[part 1 of 2: packages /DataType to /ComponentType/IvtrUSetCtrl/IvtrUSetCtrlMAIN]
AUTOSAR XML (schema 4.0)
package /DataType
  5 x app type, all with category=VALUE:
    Perc7: compu {phys=raw*0.05 for raw 0..2000; unit %}, range phys 0..100 %
    PrpsnPwrLimMin: compu {phys=raw*0.5-511 for raw 0..1022; unit kW}, range phys -511..0 kW
    Undefined: compu {identical; unit Unitless}
    T3: compu {phys=raw-50 for raw 0..250; unit degC}, range phys -50..200 degC  # Intake Air Temperature DegC
    HvCoolg1: compu {0=HvCoolg1_NoRequestForMoreCoolantPower, 1=HvCoolg1_IncreaseLevel1ForMoreCoolantPower, 2=HvCoolg1_IncreaseLevel2ForMoreCoolantPower, 3=HvCoolg1_MaxCoolingPower, 4=HvCoolg1_NotDefined; unit Unitless}, range raw 0..4
  application record data type VehModMngtGlbSafe1: category=STRUCTURE
    10 x application record element, all with category=VALUE:
      UsgModSts: compu-method=UsgModSts1, range raw 0..13, type=UsgModSts1
      CarModSts1: compu-method=CarModSts1, range raw 0..5, type=CarModSts1  # Main CarMode Data
      CarModSubtypWdCarModSubtyp: compu {identical; unit Unitless}, range phys 0..7 Unitless, type=Nr5  # CarMode Sub Data
      EgyLvlElecMai: compu {identical; unit Unitless}, range phys 0..15 Unitless, type=UInt4  # Main Data for ElEnergyLevel
      EgyLvlElecSubtyp: compu {identical; unit Unitless}, range phys 0..15 Unitless, type=UInt4  # Sub Data ElEnergyLevel
      PwrLvlElecMai: compu {identical; unit Unitless}, range phys 0..15 Unitless, type=UInt4  # Main Data for ElPowerLevel
      PwrLvlElecSubtyp: compu {identical; unit Unitless}, range phys 0..15 Unitless, type=UInt4  # Sub Data for ElPowerLevel
      FltEgyCnsWdSts: compu {0=FltEgyCns1_NoFlt, 1=FltEgyCns1_Flt; unit Unitless}, range raw 0..1, type=FltEgyCns1  # Energy Consumption Fault
      Chks: compu {identical; unit Unitless}, range phys 0..255 Unitless, type=UInt8  # End to End Checksum
      Cntr: compu {identical; unit Unitless}, range phys 0..15 Unitless, type=UInt4  # End to End Counter
  16 x app type, all with category=VALUE:
    UsgModSts1: compu-method=UsgModSts1, range raw 0..13  # UsageMode Data
    CarModSts1: compu-method=CarModSts1, range raw 0..5
    Nr5: compu {identical; unit Unitless}, range phys 0..7 Unitless  # 0= Normal 1= 2= 3= 4= 5= 6= 7=
    UInt8: compu {identical; unit Unitless}, range phys 0..255 Unitless
    UInt4: compu {identical; unit Unitless}, range phys 0..15 Unitless
    FltEgyCns1: compu {0=FltEgyCns1_NoFlt, 1=FltEgyCns1_Flt; unit Unitless}, range raw 0..1
    U2: compu {phys=raw*0.025+10.6 for raw 0..216; unit Volt}, range phys 10.6..16 Volt  # Voltage in Volt Resolution: 0.1 Range: 10.6 - 16.0 V
    I5: compu {identical; unit A}, range phys 0..254 A, invalid-value=255
    HvActvnSts: compu {0=HvActvnSts_Open, 1=HvActvnSts_Clsd, 2=HvActvnSts_KeepSt, 3=HvActvnSts_OpenAndReqActvDcha; unit Unitless}, range raw 0..3
    Perc2: compu {phys=raw*0.5 for raw 0..200; unit %}, range phys 0..100 %  # Throttle postition 0-100%
    EngSt1: compu {0=EngSt1_Ini, 1=EngSt1_Awake, 2=EngSt1_Rdy, 3=EngSt1_PreStrtg, 4=EngSt1_StrtgInProgs, 5=EngSt1_RunngRunng, 6=EngSt1_RunngStb, 7=EngSt1_RunngStrtgInProgs, 8=EngSt1_RunngRemStrtd, 9=EngSt1_AftRun; unit Unitless}, range raw 0..9
    OkNotOk1: compu {0=OkNotOk1_Ok, 1=OkNotOk1_NotOk; unit Unitless}, range raw 0..1
    UInt16: compu {identical; unit Unitless}, range phys 0..65535 Unitless
    CarTiGlb: compu {phys=raw*0.1 for raw 0..4294967295; unit s}, range phys 0..429496729.4 s, invalid-value=4.294967295E8
    DcDcActvd: compu {0=DcDcActvd_NoConversionToLVSide, 1=DcDcActvd_ConversionToLVSide; unit Unitless}, range raw 0..1
    CooltFlowForDtElec1: compu {phys=raw*0.01 for raw 0..1023; unit L / min}, range phys 0..10.23 L / min  # Flow rate in litres per minute.
  application record data type IsgTqAllwd1: category=STRUCTURE
    application record element IsgTqAllwdChks: category=VALUE, compu {phys=raw for raw 0..255; unit Unitless}, range phys 0..255 Unitless, type=Chks8  # Checksum
    application record element IsgTqAllwdCntr: category=VALUE, compu {phys=raw for raw 0..15; unit Unitless}, range phys 0..15 Unitless, type=Cntr4  # Counter
    application record element IsgTqAllwd: category=VALUE, compu {identical; unit Unitless}, range phys 0..15 Unitless, type=Nr37
  26 x app type, all with category=VALUE:
    Chks8: compu {phys=raw for raw 0..255; unit Unitless}, range phys 0..255 Unitless  # 8 bit checksum
    Nr37: compu {identical; unit Unitless}, range phys 0..15 Unitless
    Cntr4: compu {phys=raw for raw 0..15; unit Unitless}, range phys 0..15 Unitless  # 4 bit counter used in checksum calculation. N=E (modulo 16)
    SpdActInt: compu {identical; unit rpm}, range phys -INF..INF rpm
    DIOPinSts: compu {0=DIOPinSts_Low, 1=DIOPinSts_High; unit Unitless}, range raw 0..1
    NotCmpl1: compu {0=NotCmpl1_NotCmpl, 1=NotCmpl1_Cmpl; unit Unitless}, range raw 0..1  # Describe a general status as 'complete' or 'not complte'.
    N1: compu {phys=raw*0.5 for raw 0..32767; unit rpm}, range phys 0..16383.5 rpm
    ComTiOut: compu {0=ComTiOut_NoTimeout, 1=ComTiOut_Timeout; unit Unitless}, range raw 0..1
    OnOff1: compu {0=OnOff1_Off, 1=OnOff1_On; unit Unitless}, range raw 0..1
    TqInt: compu {identical; unit NewtonMeter}, range phys -50000..50000 NewtonMeter
    IsgModTyp1: compu {0=IsgModTyp1_Inin, 1=IsgModTyp1_Stb, 2=IsgModTyp1_TqCtrl, 3=IsgModTyp1_SpdCtrl, 4=IsgModTyp1_UDcCtrl, 5=IsgModTyp1_PreChrg, 6=IsgModTyp1_PwrDwn, 7=IsgModTyp1_Flt; unit Unitless}, range raw 0..7  # Coding # Meaning 0 Initialization 1 Standby 2 Torque Control 3 Speed Control 4 DC Voltage control 5 Pre-charge 6 Power-down 7 Fault
    IntFlw: compu {identical; unit L / min}, range phys -INF..INF L / min
    CooltInhb: compu {0=CooltInhb_CoolntFlowReqToEngAllwd, 1=CooltInhb_CoolntFlowReqToEngNotAllwd; unit Unitless}, range raw 0..1
    IntT: compu {identical; unit degC}, range phys -INF..INF degC
    EngTLoFlg: compu {0=EngTLoFlg_ActvLoTForEng, 1=EngTLoFlg_DeactvLoTForEng; unit Unitless}, range raw 0..1
    TInt: compu {identical; unit degC}, range phys -300..1000 degC
    ImobSnsr: compu {identical; unit Unitless}, range phys -INF..INF Unitless
    TestResult: compu {0=TestResult_NotCompleted, 1=TestResult_Failed, 2=TestResult_Passed; unit Unitless}, range raw 0..2
    EradSpdIntFloat1: compu {identical; unit rpm}, range phys -20000..20000 rpm
    TqAllwdPosAndNeg2: compu {0=TqAllwdPosAndNeg2_NoTq, 1=TqAllwdPosAndNeg2_Pos, 2=TqAllwdPosAndNeg2_Neg, 3=TqAllwdPosAndNeg2_PosAndNeg; unit Unitless}, range raw 0..3
    TqArbMgrCtrl: compu {0=TqArbMgrCtrl_TqOff, 1=TqArbMgrCtrl_TqCtrl, 2=TqArbMgrCtrl_SpdCtrl, 3=TqArbMgrCtrl_UdcCtrl; unit Unitless}, range raw 0..3
    MotCtrlMod: compu {0=MotCtrlMod_TqOff, 1=MotCtrlMod_TqOn, 2=MotCtrlMod_OffsetAngleCalibration, 3=MotCtrlMod_ActDcha, 4=MotCtrlMod_ThreePhaShoCirc; unit Unitless}, range raw 0..4
    IDcInt: compu {identical; unit A}, range phys -1000..1000 A
    HvT1: compu {phys=raw-40 for raw 0..255; unit degC}, range phys -40..215 degC
    HvU1: compu {phys=raw*0.25 for raw 0..2044; unit Volt}, range phys 0..511 Volt  # Defining the voltage data type used for HV components.
    PrpsnPwrLimMax: compu {phys=raw*0.5 for raw 0..1022; unit kW}, range phys 0..511 kW
  application record data type TqRngInt: category=STRUCTURE
    application record element Min: category=VALUE, compu {identical; unit NewtonMeter}, range phys -50000..50000 NewtonMeter, type=TqInt  # Minimum value
    application record element Max: category=VALUE, compu {identical; unit NewtonMeter}, range phys -50000..50000 NewtonMeter, type=TqInt  # Maximum value
  15 x app type:
    Boolean: category=BOOLEAN, compu {0=Boolean_FALSE, 1=Boolean_TRUE; unit Unitless}, range raw 0..1
    ActvDcha: category=VALUE, compu {0=ActvDcha_NoDischarge, 1=ActvDcha_Discharge; unit Unitless}, range raw 0..1
    HvIlckSts: category=VALUE, compu {0=HvIlckSts_HvilOpen, 1=HvIlckSts_HvilClosed; unit Unitless}, range raw 0..1
    SleepReq: category=VALUE, compu {0=SleepReq_NoRequest, 1=SleepReq_SleepRequested; unit Unitless}, range raw 0..1
    TestRequest: category=VALUE, compu {0=TestRequest_NoRequest, 1=TestRequest_TestRequested; unit Unitless}, range raw 0..1
    USetCtrlModType: category=VALUE, compu {0=USetCtrlModType_USetCtrlOff, 1=USetCtrlModType_USetCtrlOn; unit Unitless}, range raw 0..1
    SpdSetCtrlMod: category=VALUE, compu {0=SpdSetCtrlMod_SpdCtrlOff, 1=SpdSetCtrlMod_SpdCtrlExt, 2=SpdSetCtrlMod_SpdCtrlCltch, 3=SpdSetCtrlMod_SpdCtrlTrsm, 4=SpdSetCtrlMod_SpdCtrlZero; unit Unitless}, range raw 0..4
    CalJobReq: category=VALUE, compu {0=CalJobReq_NoCalReq, 1=CalJobReq_OffsetAngleCalReq; unit Unitless}, range raw 0..1
    UInt32: category=VALUE, compu {identical; unit Unitless}, range phys 0..4294967295 Unitless
    ModSts: category=VALUE, compu {0=ModSts_PreInit, 1=ModSts_LvInit, 2=ModSts_HvInit, 3=ModSts_Stb, 4=ModSts_TqCtrl, 5=ModSts_SpdCtrl, 6=ModSts_SyncnCtrl, 7=ModSts_UDcCtrl, 8=ModSts_Flt, 9=ModSts_PreSleep, 10=ModSts_ActvDcha, 11=ModSts_PreStb, 12=ModSts_GearSyncn; unit Unitless}, range raw 0..12
    ImobSts: category=VALUE, compu {0=ImobSts_ImobUndefd, 1=ImobSts_ImobImobn, 2=ImobSts_ImobMtn, 3=ImobSts_ImobNoMtn; unit Unitless}, range raw 0..3
    DiDiag: category=VALUE, compu {0=DiDiag_Disable, 1=DiDiag_Enable; unit Unitless}, range raw 0..1
    OnOff2: category=VALUE, compu {0=OnOff2_On, 1=OnOff2_Off; unit Unitless}, range raw 0..1  # PLILJESS: Autosar AI Tables Standard DATA-TYPE. Please consider using OnOff1 first hand to avoid confusion.
    TrsmVehSpd: category=VALUE, compu {phys=raw*0.01 for raw 0..65535; unit Km/h}, range phys 0..320 Km/h, invalid-value=655.35
    Perc5: category=VALUE, compu {phys=raw*0.3921568627 for raw 0..255; unit %}, range phys 0..100 %
  application record data type EngNSafe: category=STRUCTURE
    4 x application record element, all with category=VALUE:
      EngN: compu {phys=raw*0.5 for raw 0..32767; unit rpm}, range phys 0..16383 rpm, invalid-value=16383.5, type=N30
      EngNGrdt: compu {phys=raw for raw -30000..32767; unit RpmPerSec}, range phys -30000..30000 RpmPerSec, invalid-value=32767, type=NGrdt1
      EngNChks: compu {identical; unit Unitless}, range phys 0..255 Unitless, type=UInt8
      EngNCntr: compu {identical; unit Unitless}, range phys 0..15 Unitless, type=UInt4
  4 x app type, all with category=VALUE:
    N30: compu {phys=raw*0.5 for raw 0..32767; unit rpm}, range phys 0..16383 rpm, invalid-value=16383.5  # Engine speed RPM. Invalid valie 16383.5.
    NGrdt1: compu {phys=raw for raw -30000..32767; unit RpmPerSec}, range phys -30000..30000 RpmPerSec, invalid-value=32767  # Unit rpm/s
    CrashSts3: compu {0=CrashSts3_Resd1, 1=CrashSts3_NoCrash, 2=CrashSts3_Crash, 3=CrashSts3_Resd2; unit Unitless}, range raw 0..3  # Information regarding if the vehicle just has been involved in a crash, which has been detected by the SRS ECU.
    Spd6: compu {phys=raw*0.003906369 for raw -7679..7680; unit m/s}, range phys -30..30 m/s  # Generic speed data type 6
  application record data type EngT: category=STRUCTURE
    application record element EngT: category=VALUE, compu {phys=raw-50 for raw 0..250; unit degC}, range phys -50..200 degC, type=T3  # Engine coolant temperature
    application record element EngTQf: category=VALUE, compu-method=Qf1, range raw 0..3, type=Qf1  # Engine coolant temperature Qf flag
  app type Qf1: category=VALUE, compu-method=Qf1, range raw 0..3
  app type TrsmMotShiftSpdSyncnReq: category=VALUE, compu {phys=raw-16384 for raw 0..32767; unit Unitless}, range phys -16384..16383 Unitless
  app type CooltTHiResl: category=VALUE, compu {phys=raw*0.1-40 for raw 0..1800; unit degC}, range phys -40..140 degC
  application record data type UDcRngInt: category=STRUCTURE
    application record element Min: category=VALUE, compu {identical; unit Volt}, range phys -100000..100000 Volt, type=UDcInt  # Minimum value
    application record element Max: category=VALUE, compu {identical; unit Volt}, range phys -100000..100000 Volt, type=UDcInt  # Maximum value
  app type UDcInt: category=VALUE, compu {identical; unit Volt}, range phys -100000..100000 Volt
  application record data type PtTqAtAxleReMinReqRec1: category=STRUCTURE
    application record element PtTqAtAxleReMinReq: category=VALUE, compu {phys=raw for raw -20000..20000; unit NewtonMeter}, range phys -20000..20000 NewtonMeter, type=Tq2  # Minimum allowed powertrain applied torque on the rear axle
    application record element PtTqAtAxleReMinReqChks: category=VALUE, compu {identical; unit Unitless}, range phys 0..255 Unitless, type=UInt8  # Checksum
    application record element PtTqAtAxleReMinReqCntr: category=VALUE, compu {identical; unit Unitless}, range phys 0..15 Unitless, type=UInt4  # Counter
  app type Tq2: category=VALUE, compu {phys=raw for raw -20000..20000; unit NewtonMeter}, range phys -20000..20000 NewtonMeter
  app type WhlMotSysActvDampgModCodSts: category=VALUE, compu {0=WhlMotSysActvDampgModCodSts_NoDampg, 1=WhlMotSysActvDampgModCodSts_LoDampg, 2=WhlMotSysActvDampgModCodSts_MedDampg, 3=WhlMotSysActvDampgModCodSts_HiDampg; unit Unitless}, range raw 0..3  # Request of torsional active damping mode for shuffle mitigation (anti-shuffle). The signal is used to turn off anti-shuffle damping or to request extra anti-shuffle damping
  application record data type VehSpdLgtSafe1: category=STRUCTURE
    4 x application record element, all with category=VALUE:
      VehSpdLgt: compu {phys=raw*0.00391 for raw 0..31970; unit m/s}, range phys 0..125 m/s, type=Spd1  # Vehicle speed longitudinal
      VehSpdLgtQf: compu-method=GenQf1, range raw 0..3, type=GenQf1  # Qf for vehicle speed longitudinal
      VehSpdLgtCntr: compu {identical; unit Unitless}, range phys 0..15 Unitless, type=UInt4  # Counter for vehicle speed longitudinal checksum calculation
      VehSpdLgtChks: compu {identical; unit Unitless}, range phys 0..255 Unitless, type=UInt8  # Checksum for vehicle speed longitudinal
  app type Spd1: category=VALUE, compu {phys=raw*0.00391 for raw 0..31970; unit m/s}, range phys 0..125 m/s
  app type GenQf1: category=VALUE, compu-method=GenQf1, range raw 0..3
  app type PtActrMod1: category=VALUE, compu {0=PtActrMod1_NoReq, 1=PtActrMod1_ActrMod1, 2=PtActrMod1_ActrMod2, 3=PtActrMod1_ActrMod3; unit Unitless}, range raw 0..3
  application record data type PwrRngInt: category=STRUCTURE
    application record element Min: category=VALUE, compu {identical; unit kW}, range phys -20000..20000 kW, type=PwrInt  # Minimum Value
    application record element Max: category=VALUE, compu {identical; unit kW}, range phys -20000..20000 kW, type=PwrInt  # Maximum Value
  app type PwrInt: category=VALUE, compu {identical; unit kW}, range phys -20000..20000 kW
  app type PtTqType: category=VALUE, compu {phys=raw-1024 for raw 0..2047; unit NewtonMeter}, range phys -1024..1023 NewtonMeter
  application record data type VehMtnStSafe1: category=STRUCTURE
    application record element VehMtnSt: category=VALUE, compu-method=VehMtnSt2, range raw 0..7, type=VehMtnSt2  # Vehicle motion state
    application record element VehMtnStChks: category=VALUE, compu {identical; unit Unitless}, range phys 0..255 Unitless, type=UInt8  # Checksum for vehicle motion state
    application record element VehMtnStCntr: category=VALUE, compu {identical; unit Unitless}, range phys 0..15 Unitless, type=UInt4  # Counter for vehicle motion state
  app type VehMtnSt2: category=VALUE, compu-method=VehMtnSt2, range raw 0..7
  app type CooltLoFlow: category=VALUE, compu {phys=raw*0.5 for raw 0..40; unit L / min}, range phys 0..20 L / min
  application record data type Rec32ByteU32ReadFlg: category=STRUCTURE
    9 x application record element, all with category=VALUE:
      MemReadFlg: compu {0=OkNotOk_NotOk, 1=OkNotOk_Ok; unit Unitless}, range raw 0..1, type=OkNotOk  # Memory has been read from memory and has been checked for corruption.
      Byte00To03: compu {identical; unit Unitless}, range phys 0..4294967295 Unitless, type=UInt32  # Byte 00 to 03 in big endian byte order.
      Byte04To07: compu {identical; unit Unitless}, range phys 0..4294967295 Unitless, type=UInt32  # Byte 04 to 07 in big endian byte order.
      Byte08To11: compu {identical; unit Unitless}, range phys 0..4294967295 Unitless, type=UInt32  # Byte 08 to 11 in big endian byte order.
      Byte12To15: compu {identical; unit Unitless}, range phys 0..4294967295 Unitless, type=UInt32  # Byte 12 to 15 in big endian byte order.
      Byte16To19: compu {identical; unit Unitless}, range phys 0..4294967295 Unitless, type=UInt32  # Byte 16 to 19 in big endian byte order.
      Byte20To23: compu {identical; unit Unitless}, range phys 0..4294967295 Unitless, type=UInt32  # Byte 20 to 23 in big endian byte order.
      Byte24To27: compu {identical; unit Unitless}, range phys 0..4294967295 Unitless, type=UInt32  # Byte 24 to 27 in big endian byte order.
      Byte28To31: compu {identical; unit Unitless}, range phys 0..4294967295 Unitless, type=UInt32  # Byte 28 to 31 in big endian byte order.
  4 x app type, all with category=VALUE:
    OkNotOk: compu {0=OkNotOk_NotOk, 1=OkNotOk_Ok; unit Unitless}, range raw 0..1
    IsgMotCooltFlow: compu {phys=raw*0.05 for raw 0..1023; unit L / min}, range phys 0..51.15 L / min
    HvI1: compu {phys=raw*0.1-410 for raw 0..8191; unit A}, range phys -410..409.1 A
    DchaAvl: compu {0=DchaAvl_NotAvailable, 1=DchaAvl_Available, 2=DchaAvl_BackupOnly, 3=DchaAvl_Reserved; unit Unitless}, range raw 0..3
  application record data type ImobEngChk: category=STRUCTURE
    8 x application record element, all with category=VALUE:
      ImobEngChkSts: compu {0=AvlSts2_NotAvl, 1=AvlSts2_Avl; unit Unitless}, range raw 0..1, type=AvlSts2  # Message to CEM Challenge available
      ImobEngDataChk{0..6}: compu {identical; unit Unitless}, range phys 0..255 Unitless, type=UInt8  # Byte {0..6}
  app type AvlSts2: category=VALUE, compu {0=AvlSts2_NotAvl, 1=AvlSts2_Avl; unit Unitless}, range raw 0..1  # Availability status 0= not available 1= available
  app type ImobMemSts: category=VALUE, compu {identical; unit Unitless}, range phys 0..255 Unitless
  application record data type ImobEngMgrReq: category=STRUCTURE
    8 x application record element, all with category=VALUE:
      ImobEngMgrCmdTar1: compu-method=ImobEngMgrReqCmd, range raw 0..3, type=ImobEngMgrReqCmd  # Command from CEM
      ImobEngDataMgrReq{0..6}: compu {identical; unit Unitless}, range phys 0..255 Unitless, type=UInt8  # Byte {0..6}
  app type ImobEngMgrReqCmd: category=VALUE, compu-method=ImobEngMgrReqCmd, range raw 0..3
  app type IsgSpd1: category=VALUE, compu {identical; unit rpm}, range phys 0..8191 rpm  # ISG speed referred to crankshaft.
  application record data type VehCfgPrm: category=STRUCTURE
    8 x application record element, all with category=VALUE, compu {phys=raw for raw 0..255; unit Unitless}, range phys 0..255 Unitless, type=Nr2:
      BlkIDBytePosn1  # Block ID for specific Car Configuration parameter sequence
      CCPBytePosn2  # 1st position in specific CCP number sequence - Block ID dependant
      CCPBytePosn3  # 2nd position in specific CCP number sequence - Block ID dependant
      CCPBytePosn4  # 3rd position in specific CCP number sequence - Block ID dependant
      CCPBytePosn5  # 4th position in specific CCP number sequence - Block ID dependant
      CCPBytePosn6  # 5th position in specific CCP number sequence - Block ID dependant
      CCPBytePosn7  # 6th position in specific CCP number sequence - Block ID dependant
      CCPBytePosn8  # 7th position in specific CCP number sequence - Block ID dependant
  app type Nr2: category=VALUE, compu {phys=raw for raw 0..255; unit Unitless}, range phys 0..255 Unitless
  app type HvFltInfo1: category=VALUE, compu {0=HvFltInfo1_NoFlt1, 1=HvFltInfo1_ElecMotFlt, 2=HvFltInfo1_ShoCircMotAcPha, 3=HvFltInfo1_InvrNoHvDc, 4=HvFltInfo1_InvrFlt1, 5=HvFltInfo1_ShoCircDcPha, 6=HvFltInfo1_Undefined1; unit Unitless}, range raw 0..6  # Datat type defining the different fault states which are applicable for the inverter fault signal.
  app type Len31: category=VALUE, compu {phys=raw for raw 0..2000000; unit km}, range phys 0..2000000 km
  application record data type LvlElecSts1: category=STRUCTURE
    application record element LvlElecMai: category=VALUE, compu {identical; unit Unitless}, range phys 0..15 Unitless, type=UInt4
    application record element LvlElecSubtyp: category=VALUE, compu {identical; unit Unitless}, range phys 0..15 Unitless, type=UInt4
  application record data type SysU: category=STRUCTURE  # System voltage represented by the CEM node Voltage
    application record element SysU: category=VALUE, compu {phys=raw*0.1 for raw 0..250; unit Volt}, range phys 0..25 Volt, type=U1  # System Voltage
    application record element SysUQf: category=VALUE, compu-method=GenQf1, range raw 0..3, type=GenQf1  # System voltaeg quality factor
  app type U1: category=VALUE, compu {phys=raw*0.1 for raw 0..250; unit Volt}, range phys 0..25 Volt
  application record data type IsgTqActSafe1: category=STRUCTURE  # Record for IsgTqAct E2E protection.
    4 x application record element, all with category=VALUE:
      Cntr: compu {identical; unit Unitless}, range phys 0..15 Unitless, type=UInt4  # Counter signal for IsgTqAct
      Chks: compu {identical; unit Unitless}, range phys 0..255 Unitless, type=UInt8  # Checksum signal for IsgTqAct
      IsgTqAct: compu {phys=raw-1024 for raw 0..2047; unit NewtonMeter}, range phys -1024..1023 NewtonMeter, type=PtTqType  # Torque actual signal
      QualityFactor: compu-method=QualityFactor, range raw 0..3, type=QualityFactor  # Quality factor signal for IsgTqAct
  app type QualityFactor: category=VALUE, compu-method=QualityFactor, range raw 0..3
  application record data type IsgTqAvl: category=STRUCTURE
    application record element IsgTqAvlMax: category=VALUE, compu {phys=raw-1024 for raw 0..2047; unit NewtonMeter}, range phys -1024..1023 NewtonMeter, type=PtTqType  # Maximum available torque from ISG on wheel shaft
    application record element IsgTqAvlMin: category=VALUE, compu {phys=raw-1024 for raw 0..2047; unit NewtonMeter}, range phys -1024..1023 NewtonMeter, type=PtTqType  # Minimum available torque from ISG on wheel shaft
  app type LimnIndcnDcDc: category=VALUE, compu {identical; unit Unitless}, range phys 0..65535 Unitless
  app type DevErrSts2: category=VALUE, compu {0=DevErrSts2_NoFlt, 1=DevErrSts2_Flt; unit Unitless}, range raw 0..1
  app type Pwr3: category=VALUE, compu {phys=raw*20 for raw 0..1023; unit W}, range phys 0..20460 W  # Charging power.
package /DataType/DataTypeSemantics
  compu method UsgModSts1: 0=UsgModSts1_UsgModAbdnd, 1=UsgModSts1_UsgModInActv, 2=UsgModSts1_UsgModCnvinc, 11=UsgModSts1_UsgModActv, 13=UsgModSts1_UsgModDrvg; unit Unitless
  compu method CarModSts1: 0=CarModSts1_CarModNorm, 1=CarModSts1_CarModTrnsp, 2=CarModSts1_CarModFcy, 3=CarModSts1_CarModCrash, 5=CarModSts1_CarModDyno; unit Unitless
  compu method Qf1: 0=Qf1_DevOfDataUndefd, 1=Qf1_DataTmpUndefdAndEvlnInProgs, 2=Qf1_DevOfDataNotWithinRngAllwd, 3=Qf1_DataCalcdWithDevDefd; unit Unitless
  compu method GenQf1: 0=GenQf1_UndefindDataAccur, 1=GenQf1_TmpUndefdData, 2=GenQf1_DataAccurNotWithinSpcn, 3=GenQf1_AccurData; unit Unitless
  compu method VehMtnSt2: 0=VehMtnSt2_Ukwn, 1=VehMtnSt2_StandStillVal1, 2=VehMtnSt2_StandStillVal2, 3=VehMtnSt2_StandStillVal3, 4=VehMtnSt2_RollgFwdVal1, 5=VehMtnSt2_RollgFwdVal2, 6=VehMtnSt2_RollgBackwVal1, 7=VehMtnSt2_RollgBackwVal2; unit Unitless
  compu method ImobEngMgrReqCmd: 0=ImobEngMgrReqCmd_ImobEngCmdTarIdle, 1=ImobEngMgrReqCmd_ImobEngMtnStrtReqCmd, 2=ImobEngMgrReqCmd_ImobEngNoMtnStrtReqCmd, 3=ImobEngMgrReqCmd_ImobEngTurnOffCmd; unit Unitless
  compu method QualityFactor: 0=QualityFactor_QfUndefd, 1=QualityFactor_QfInProgs, 2=QualityFactor_QfNotSpc, 3=QualityFactor_QfSnsrDataOk; unit Unitless
package /DataType/DataTypeUnits
  physical dimension PercPD
  unit Perc: display-name=%, physical-dimension=PercPD  # 0-100
  physical dimension KiloWattPD
  unit KiloWatt: display-name=kW, physical-dimension=KiloWattPD  # Power
  physical dimension NoUnitPD
  unit NoUnit: display-name=Unitless, physical-dimension=NoUnitPD
  physical dimension DegCgrdPD: temperature-exp=1
  unit DegCgrd: display-name=degC, factor-si-to-unit=1.0, offset-si-to-unit=-273.15, physical-dimension=DegCgrdPD  # Degree Centigrade temperature, no SI unit, (degC = Kelvin - 273.15)
  physical dimension VoltPD: length-exp=2, mass-exp=1, time-exp=-3, current-exp=-1
  unit Volt: display-name=Volt, factor-si-to-unit=1.0, offset-si-to-unit=0.0, physical-dimension=VoltPD  # Electric potential difference (derived from SI units)
  physical dimension AmprPD
  unit Ampr: display-name=A, physical-dimension=AmprPD  # Electrical curren, Ampere
  physical dimension SecPD: time-exp=1
  unit Sec: display-name=s, factor-si-to-unit=1.0, offset-si-to-unit=0.0, physical-dimension=SecPD  # SI base unit of time
  physical dimension LPerMinsPD
  unit LPerMins: display-name=L / min, physical-dimension=LPerMinsPD  # Litres per minute
  physical dimension RpmPD
  unit Rpm: display-name=rpm, physical-dimension=RpmPD
  physical dimension NmPD
  unit Nm: display-name=NewtonMeter, physical-dimension=NmPD  # Newton meter Si-unit.
  physical dimension KiloMtrPerHrPD
  unit KiloMtrPerHr: display-name=Km/h, physical-dimension=KiloMtrPerHrPD  # The unit kilometers per hour
  physical dimension RpmPerSecPD
  unit RpmPerSec: display-name=RpmPerSec, physical-dimension=RpmPerSecPD
  physical dimension MtrPerSecPD: length-exp=1, time-exp=-1
  unit MtrPerSec: display-name=m/s, physical-dimension=MtrPerSecPD  # Velocity (derived from SI units)
  physical dimension kmPD: length-exp=1
  unit km: display-name=km, factor-si-to-unit=0.0010, offset-si-to-unit=0.0, physical-dimension=kmPD  # 1000 m
  physical dimension WattPD
  unit Watt: display-name=W, physical-dimension=WattPD  # Electric power.
package /PortInterface
  191 x sender receiver interface:
    PIHvBattSocA77320FF1C91A350F2BA301C1CAC402F
      data HvBattSoc: type=Perc7  # Actual state of charge of the Hv Battery.
    PIIsgPwrLimMinAA0AD33737EA8E8595F5A245D8A01AAE
      data IsgPwrLimMin: type=PrpsnPwrLimMin  # Minimum ISG motor drive system powerlimit on DC side. Positive power means power flowing into inverter.
    PICoolgTAEBBC0E0BF9D0B867FC539280BD2C2EB
      data CoolgT: type=Undefined
    PIMotTIsgA09B376373D0232B676B5E6DBBCD1B03
      data MotTIsg: type=T3  # Temperature of the CISG
    PIDcDcCoolgReqA025114FAC3219ECDC2C16CD8D7EA254
      data DcDcCoolgReq: type=HvCoolg1  # Request for increased cooling flow to DCDC
    PIVehModMngtGlbSafe1ACB5AA28F7735E6F58D320F1795FA9D2
      data VehModMngtGlbSafe1: type=VehModMngtGlbSafe1  # VehModMngtGlbSafe1 is a system signal group sent globally in an end to end protected record that consists of CarModSts1, CarModSubtypWdCarModSubtyp, UsgModSts, EgyLvlElecMai, EgyLvlElecSubtyp, PwrLvlElecMai, PwrLvlElecSubtyp and FltEngyCnsWdSts CarModSts1 : Factory, Transport, Dyno, Normal. Crash UsgModSts : Abandoned, Inactive, Convenience, Active, Driving CarModSubtypWdCarModSubtyp: examples for CarModSubtyp: Factory Driving, Transport Driving
    PIChrgnUReqABDC99F9167D30ECF66FA96FF394DC82
      data ChrgnUReq: type=U2  # Requested Charging voltage from Voltage Control
    PICoolgReqInvrIsg1A90DA089E64278CDEC91FE617833644E
      data CoolgReqInvrIsg1: type=HvCoolg1  # Request for increased cooling flow to Inverter
    PIIDcDcActLoSideAB86FC040C6B68F76DC289353488FF07
      data IDcDcActLoSide: type=I5  # The current output on the LV side
    PIHvSysRlyStsA2ECDBA6F424314678356310156CB116
      data HvSysRlySts: type=HvActvnSts  # Actual state of the contactors. Open: MAIN or NEG opend (Hv circuit open). Closd: Both MAIN and NEG closed (Hv circuit closed). KeepSt: Init value/value when state not known. OpenAndReqActvDcha: Hv circuit open and request for Hv system discharge.
    PIThrPosA25972D14A9A311E909336B3DE119F20
      data ThrPos: type=Perc2  # ECM throttle position (AbsThrottlePosition) on CAN
    PIEngSt1WdStsA2155BE2B5E559698249D58FD6834766
      data EngSt1WdSts: type=EngSt1  # Signaling the state of the powerpack.
    PIMaxCrkPfmncReqA0C659E8F9D27F75BF2380EAE0AA9F4B
      data MaxCrkPfmncReq: type=OkNotOk1
    PIIsgLimnIndcnADF19BF242836C0A707BE92B67A1A3C9
      data IsgLimnIndcn: type=UInt16
    PICarTiGlbAA389EC7D8A8D9B4AA13475919A8FFBB
      data CarTiGlb: type=CarTiGlb  # Presents a tiime value that shall be used by all ECUs to time-stamp diagnsotic trouble codes (DTC) according to the requirements for Global DTC snapshot data.
    PIDcDcActvdReqA302D3884E8C2093F934F0B3D9C4B780
      data DcDcActvdReq: type=DcDcActvd  # Signal requesting the DCDC to be activated after conditions are fullfilled.
    PICooltFlowForDtElecAE708B662153AB35A8AE5AAB5AB27F45
      data CooltFlowForDtElec: type=CooltFlowForDtElec1  # PredictedCoolant flow for Electric Drivetrain (ED) coolant circuit.
    PIIsgTqAllwdA7BF5C6A27E4AC2E1132408CBC9D658A
      data IsgTqAllwd: type=IsgTqAllwd1  # Indication if ISG is allowed to apply propulsive or regenerative torque on wheels. Bit 0: Propulsive torque allowed Bit 1: Regenerative torque allowed
    PIIDcDcAvlMaxLoSideABECA9784581B76EA605F26FB2B0C603
      data IDcDcAvlMaxLoSide: type=I5  # Maximum available output current from the DcDc to the LV side
    PIHvBattSocIntAF995C1025A34F2949242ACBE8774947
      data HvBattSocInt: type=Perc7  # Battery state of charge. Needed for freeze frame data.
    PIElecMotSpdExtA153CF90F14E0A67B2004C713EAF537C
      data ElecMotSpdExt: type=SpdActInt  # Electric motor axle speed as meassured by other ECU(s). The source of the information depends on the application.
    PICPSRStsA8A4347A34501F85AC0E2F846ED365D2
      data CPSRSts: type=DIOPinSts  # Status of the CPSR input pin. The information is used during startup and shutdown.
    PIPrpsnSysActvADF201E67A5F2AD43772741F7E0BC64C
      data PrpsnSysActv: type=NotCmpl1
    PIIsgSpdReqA2F193D1CDBCA4ED9BE33726009A33F1
      data IsgSpdReq: type=N1  # ISG speed request for engine speed control by ISG.
    PITqReqTiOutAA0375BA52699CEBC8EFC335771F9292
      data TqReqTiOut: type=ComTiOut  # CAN signal timeout for the torque request.
    PIIsgErrIndcnReqA7481018ECF7E1FBAD4F2094346D0B08
      data IsgErrIndcnReq: type=OnOff1  # MIL ilumination req from IGM
    PITqEstInt1A7271F3966F592BF2D62AC08EA215058
      data TqEstInt1: type=TqInt  # Internal version of the CAN signal for estimated torque, only the QM part. Needs to be updated every 1 ms.
    PIModStsIsgA7044F728F241DA596978E555892168B
      data ModStsIsg: type=IsgModTyp1
    PICooltFlowForDtElecInt1A9FECD6244DBBCFF94A4D3481557ACF8
      data CooltFlowForDtElecInt1: type=IntFlw  # Coolant flow in the low temperature cooling circuit used by electric drive train.
    PIEngCooltInhbFlowIntA43645F8FC8EF56D979D27462C05E480
      data EngCooltInhbFlowInt: type=CooltInhb
    PICoolgFlwIntACEE92072173D1CFD40FC332400B8271
      data CoolgFlwInt: type=IntFlw  # Coolant flow in the high temperature cooling circuit used by the combustion engine.
    PICoolgTIntA164FA54A249BFDCCE1036A75E5B64AF
      data CoolgTInt: type=IntT  # Coolant temperature in the high temperature cooling circuit used by the combustion engine.
    PIIsgMotCooltTFlgIntA111E842B5100FA6235090DA6780D515
      data IsgMotCooltTFlgInt: type=EngTLoFlg
    PICoolgReqIntAC96DF3F9C8D1E3AF241978EA9887249
      data CoolgReqInt: type=HvCoolg1
    PIIvtrTIntA1ADB999FA62ACDB6E7B4DDFD2507DC5
      data IvtrTInt: type=TInt  # Highest or most relevant temperature meassured in the inverter.
    PIIsgMotCooltFlowReqIntA19C72CF8CA9A562AA4BC89712FF8931
      data IsgMotCooltFlowReqInt: type=IntFlw
    PICooltTSigForDtElecIntA2FA3C44D4A64B3BD19E1FAA3F5036C0
      data CooltTSigForDtElecInt: type=IntT  # Coolant temperature of the low temperature cooling circuit used by electric drive train.
    PIElecMotTActIntA31764229174765644BFC492C91799B4
      data ElecMotTActInt: type=TInt  # Measured EM temperature. Updated at least every 20 ms
    PIHvSysRlyStsTiOutA38DC641039478964364ABA0D9653B7F
      data HvSysRlyStsTiOut: type=ComTiOut  # CAN signal timeout for HvSysRlySts
    PIRawSnsr3A1F68F82F3621DD4600B4515DA742FAA
      data RawSnsr3: type=ImobSnsr  # Raw unfiltered random value from the HW
    PIHvSysRlyStsIntAE97F692199F8010A699D6E6558D46BB
      data HvSysRlyStsInt: type=HvActvnSts  # Battery contactor status. No required use by the supplier except for Freeze Frame Data.
    PILvTestStsA2189E54DE0AD78B08D617DE031D72CB
      data LvTestSts: type=TestResult  # Result from LV tests
    PIPrpsnSysActvIntA9E07D613D353B72E4229687608CB35B
      data PrpsnSysActvInt: type=NotCmpl1
    PITqReqMotAA0613566B952B165886BB90ACC9A333
      data TqReqMot: type=TqInt  # The torque request from VCC to supplier 1ms
    PITqReqIntA5D6B18A182E3E3163E8C10423C7BF7B
      data TqReqInt: type=TqInt
    PITqReqIntFromAntiSpinA3E0985D2188AEE4DF3A78C4373D692A
      data TqReqIntFromAntiSpin: type=TqInt
    PISpdActIntA6A96BD3DA561BF55CACA28E83811FE5
      data SpdActInt: type=EradSpdIntFloat1
    PITqReqFromUSetCtrlA1DCACFFC54FBD504C97AB823DEC438C
      data TqReqFromUSetCtrl: type=TqInt
    PITqReqFromTqArbMgrSlowACFA7EBE680724BB6B16A7641540B266
      data TqReqFromTqArbMgrSlow: type=TqInt
    PITqReqFromStabyCtrlAE3334B4A8203F15CF4D44D6347AB2D9
      data TqReqFromStabyCtrl: type=TqInt
    PITqAllwdIntAF9EFDC17B77F69A6AF9F6C69ECF29C7
      data TqAllwdInt: type=TqAllwdPosAndNeg2  # QM part of the Torque Allowed signal on CAN.
    PITqArbMgrCtrlAFB3CB54536D18B2730B1F2D7C289A9B
      data TqArbMgrCtrl: type=TqArbMgrCtrl
    PITqReqFromSpdSetCtrlA6EF4449479B0DD7E99F884852E50B53
      data TqReqFromSpdSetCtrl: type=TqInt
    PIMotCtrlModReqAC12411DA8E7F4DA2D4D74FCE273A6CD
      data MotCtrlModReq: type=MotCtrlMod  # Request signal for motor control mode
    PIIDcIntADC6E4AABF9E9CA078F15C71E21B8CCC
      data IDcInt: type=IDcInt  # Current between HVDC and inverter. Positive values for motoring. Needs to updated at least every 10 ms.
    PIIsgCooltTA2201BA89308C9DB96BC35C0437C1E0E
      data IsgCooltT: type=HvT1  # Measured coolant temperature in inverter
    PIUDcIsgABC381DB11B823825EA91E5C8A9929FF
      data UDcIsg: type=HvU1
    PIIsgPwrLimMaxA2BEE741673FE17DC30D9DDF9B2DA05E
      data IsgPwrLimMax: type=PrpsnPwrLimMax  # Maximum ISG motor drive system powerlimit on DC side. Positive power means power flowing into inverter.
    PITqAvlIntFromIfCptA143A45B4C3E7EDAB91B3431BED4F1CC
      data TqAvlIntFromIfCpt: type=TqRngInt  # Available torque including all deratings on supplier side
    PIAntiSpinOnOffAC1D0778A0EC80A96F7D2813A7BB259C
      data AntiSpinOnOff: type=OnOff1
    PITqEstAccuracyFailedA4F2A595E6B812A8ABFB998FFD3DDAAF
      data TqEstAccuracyFailed: type=Boolean  # Failed to perform the torque estimation
    PIInitCmplAB5613B7F20140A52C7365223575BDAA
      data InitCmpl: type=Boolean  # Supplier is finished with initialization
    PIPwrDcLimnOnOffA716253C078B85207271B150130ACE4C
      data PwrDcLimnOnOff: type=OnOff1
    PIImobEngTurnOffAllwd3A8E33815F2A5CA56ED918D0B41C26BA7
      data ImobEngTurnOffAllwd3: type=Boolean  # Message to IGM basic software regarding if it is allowed to shut down the node
    PIIDcLimnOnOffA1A0D687EB68B5446961073602258F9F
      data IDcLimnOnOff: type=OnOff1
    PISpdLimnOnOffAF27A08CD1270A105DC7D1D829F2DFFC
      data SpdLimnOnOff: type=OnOff1
    PIActvDchaReqABDBFDA592F4FD97AEC36B8942FC52D1
      data ActvDchaReq: type=ActvDcha  # Request signal for performing active discharge
    PIHvIlckStsA1EFC296397BCC9F3CEBEEDA3BC51166
      data HvIlckSts: type=HvIlckSts  # HV AC interlock status
    PIImobEngTurnOffAllwdIntA6F00424669E1DD01BF13F084E9A5B01
      data ImobEngTurnOffAllwdInt: type=Boolean
    PIPrepSleepReqA79D9A92893359CCF00419107A34F584
      data PrepSleepReq: type=SleepReq  # Commmiunication manager is in no-communication state.
    PITrsmMotShiftSyncnModReqIntA690B98D28F58708C7741593A47EC6F4
      data TrsmMotShiftSyncnModReqInt: type=IsgModTyp1
    PISleepAllwdA540431CFC6EA214AA8D1D1BCAAED0DA
      data SleepAllwd: type=Boolean  # ECU Allowed to perform shutdown actions (write NvM) and go to sleep. When this signal is activated the ECU will power down.
    PIMplRunngRstAC51CAEF17C1D68D8F9247B258E26918
      data MplRunngRst: type=Boolean  # Indicates to the mode manager if multiple resets has occured within a certain time interval
    PILvTestReqA79CDD19DF2BF673149BDB28B02B946E
      data LvTestReq: type=TestRequest  # Request signal to start LV tests. Transision from "No Request" to "Text Requested" should trigger the test.
    PIHvBattUDcIntA8F551FC6F364EFFE50EFDEF09959371
      data HvBattUDcInt: type=HvU1  # Battery voltage meassured on the battery, inside the contactors. No required use by the supplier, but may be used for plausibility checks etc. VCC might use it to check progress of Active Discharge.
    PIUSetCtrlModA5DAD94277F1523660C82246E9CA1AEB
      data USetCtrlMod: type=USetCtrlModType
    PISpdSetCtrlModAFC5301B7771F23DB9D5EE6AC427D0DF
      data SpdSetCtrlMod: type=SpdSetCtrlMod
    PICalReqAB866D96E991BDFE56BBA8080ABDEE2B
      data CalReq: type=CalJobReq  # Signals if workshop/production tools have requested calibration. Set on UDS service request, cleared when motor core is done (failed or successful).
    PIIvtrErrStsA48548CF9954C363177D6EDCE964A414
      data IvtrErrSts: type=UInt32  # Bit-field with one bit per detectable fault in the supplier software. 0 = no fault, 1 = fault present
    PIMaxCrkPfmncReqIntA111564D31BCD647B56C1ED2AC778042
      data MaxCrkPfmncReqInt: type=OnOff1
    PIUDcLimnOnOffA5879E3E270A3C90663D5138C02CA256
      data UDcLimnOnOff: type=OnOff1
    PIStabyCtrlOnOffA0177C9985E523EACC25F2501718EFA6
      data StabyCtrlOnOff: type=OnOff1
    PIModStsIntA0974E28C4191E7BEB73E601D4BF6671
      data ModStsInt: type=ModSts
    PIElecMotTLimnOnOffA56EC985B47DAFBF769445C481FDAB70
      data ElecMotTLimnOnOff: type=OnOff1
    PIMotCtrlModStsA1697EA7CF5F8F95BE310EB812C577CA
      data MotCtrlModSts: type=MotCtrlMod  # Contains the current mode of operation of the motor core.
    PIModReqIntA9B51427AA190B5B37343F579430CE9F
      data ModReqInt: type=ModSts
    PIImobLastStsIntA9ADABD561EEBF179852E5E0020F68FB
      data ImobLastStsInt: type=ImobSts
    PITqEstAccuracyViolationABA54935243925EDCBC2DC8B5C54F204
      data TqEstAccuracyViolation: type=Boolean  # Violation of the torque estimation
    PIHvTestReqA8AC458AD30AB54A714AC4B452027B51
      data HvTestReq: type=TestRequest  # Request signal to start HV tests. Transision from "No Request" to "Text Requested" should trigger the test.
    PIEngSt1WdStsIntA984173EA88CF4430E5B4D577A9BEE8A
      data EngSt1WdStsInt: type=EngSt1  # Signaling the state of the combustion engine. Used for Freeze Frame Data. Also used for disabling under voltage protection/limitation while engine start is in progress.
    PIHVDCDiagDisabledA9D522799F865BF0CAEA36CC194489F7
      data HVDCDiagDisabled: type=DiDiag  # Disable HVDC diagnostics
    PIHvTestStsA0081D64681C391764F24F920F8A06AB
      data HvTestSts: type=TestResult  # Result from HV test
    PIRawSnsr2A1689E6366591FDF1F07EB5737A7F784
      data RawSnsr2: type=ImobSnsr  # Raw unfiltered random value from the HW
    PIThrPosIntA20D477FF7A668DC3230A135B89198F2
      data ThrPosInt: type=Perc2  # Throttle position used for freeze frame
    PIDeactvtTextComIntA412C5C4188DBD312EBDD4AACDF5606F
      data DeactvtTextComInt: type=OnOff2
    PITrsmVehSpdA530EB39B7F0C03CD74B694A6233FCF8
      data TrsmVehSpd: type=TrsmVehSpd  # Vehicle speed measured by transmission
    PIIvtrLimnStsA2DC56C33F00DC87714A5BD82253D1CF
      data IvtrLimnSts: type=UInt16  # Signals if the IGBT derating model have derated the output torque. The reason for the limitation is bit mapped.
    PILoadValCalcdIntA4155C00BC6967674B3601924F63EF93
      data LoadValCalcdInt: type=Perc5
    PITqAvlPostDmpgA8A2225F69096486DAF4FE31FFE52A89
      data TqAvlPostDmpg: type=TqRngInt
    PITqAvlPreDmpgA3BBD89CD0B70EA59A15EEA68F5001F0
      data TqAvlPreDmpg: type=TqRngInt
    PITqCorrnFromAntiShuffleCtrlAD33CF95663C108692593B0CC185952D
      data TqCorrnFromAntiShuffleCtrl: type=TqInt
    PIIsgMotCooltTFlgAF2570A795F208C7164D4E692AD44EF5
      data IsgMotCooltTFlg: type=EngTLoFlg  # Request for lower coolant temperature for the CISG
    PIEngNSafeA13040C42CDFF66783CAED0F5F3A0B17
      data EngNSafe: type=EngNSafe  # Engine Speed [rpm] Engine Speed derivative [rpm/s]
    PIHvBattUDynMaxLimAA62A1D48367E62EA294DC5CAB54933C
      data HvBattUDynMaxLim: type=HvU1  # The pack voltage high limit of the Hv Battery, dynamically based on cell voltage distribution. At pack voltages above this limit, there is risk for contactor openeing due to too high cell voltage.
    PICrashSts2A01AE2778BB77865FCC5765A417E5EC0
      data CrashSts2: type=CrashSts3  # Information if a crash has been detected by SRS.
    PIImobLastStsA8887E0FF05A13A82EF1D5B8DF73E036
      data ImobLastSts: type=ImobSts
    PIPrpsnFbLimnIndcnA8C29516BF74EB4BE772A04D646D70E9
      data PrpsnFbLimnIndcn: type=UInt4  # Feedback signal that the present limitation has lead to a recofiguraton that has affected the driver.
    PIAxleSlipRelActIntAC155C8C29B9B6D5EA131B477AEAA643
      data AxleSlipRelActInt: type=Spd6
    PIEngTInt1A7012310C427A47E167742A32C97EB0F
      data EngTInt1: type=EngT  # Engine temperature. Used for freeze frame data.
    PITrsmMotShiftSpdSyncnReqAF50800ED4E965216A820B6F93CDEA6B
      data TrsmMotShiftSpdSyncnReq: type=TrsmMotShiftSpdSyncnReq
    PIHvBattUDcA1C06600AEE00B3D0C9C6D390C8BBBC1
      data HvBattUDc: type=HvU1  # Actual Hv Battery pack voltage (measuered before contactors, i.e. always giving pack voltage).
    PICooltTSigForDtElecA8F9553C734340EA3B15034831232D8D
      data CooltTSigForDtElec: type=CooltTHiResl  # Coolant temperature for the Electric Drivetrain (ED) cooling circuit.
    PIHvBattUDynLimIntA43240D48561C3809D26B0DDADA0994C
      data HvBattUDynLimInt: type=UDcRngInt
    PIMonrCycCmplIntA79D4FDEDFCA208EE98A11B4143D332E
      data MonrCycCmplInt: type=NotCmpl1
    PISpdIdleReqIntA120A3344BF6F92279B860A9FAA6ECAE
      data SpdIdleReqInt: type=N1
    PIPtTqAtAxleReMinReqIntAFD19582F9E5351499AF05A089486D9F
      data PtTqAtAxleReMinReqInt: type=PtTqAtAxleReMinReqRec1
    PIMonrCycCmplAFA85F4459D5954FCEFB9C4EAE92D0A0
      data MonrCycCmpl: type=NotCmpl1  # OBD Warm Up Cycle Complete. 0= Not Complete 1= Complete
    PICrashSts2IntA568E96275CC7FD119BC41146A8D528D
      data CrashSts2Int: type=CrashSts3
    PISpdRotlForWhlsAtAxleReIntA6D8442B2DF57AE61F7FA90FE332F100
      data SpdRotlForWhlsAtAxleReInt: type=N1
    PIIsgEngSpdOfActvDampgAB63CB64F3204234FE4ABC77BFA3477D
      data IsgEngSpdOfActvDampg: type=N1  # Engine speed target for ISG damping function.
    PIIsgActvDampgModReqA8E90769C8B59C2651DDABA1191E244E
      data IsgActvDampgModReq: type=WhlMotSysActvDampgModCodSts  # Mode signal for ISG damping. 0 = No damping 1 = Low damping 2 = Medium damping 3 = High damping
    PIVehSpdLgtSafeIntAD8AC096042D649E5EC87B3898F1B812
      data VehSpdLgtSafeInt: type=VehSpdLgtSafe1
    PIDeactvtTestComA82AAD4A52C680CF62EA318A5104AC68
      data DeactvtTestCom: type=OnOff2  # Scantool communication on/ff 0=on=scantool communication is on 1=off=scantool communication is off
    PIPtActrReModReqIntAC7CB0D3EAAE60316C1534B0170413A6
      data PtActrReModReqInt: type=PtActrMod1
    PIPwrLimIntAD41D62306877041EEB8FC4C60191431
      data PwrLimInt: type=PwrRngInt
    PITrsmMotShiftSyncnModReqA77B7144C789FDC8A8DF5097F76BCE02
      data TrsmMotShiftSyncnModReq: type=IsgModTyp1
    PILoadValCalcdA71AA47E92305AFFB5226EB64D908D0B
      data LoadValCalcd: type=Perc5  # The ECU shall make the signal Calculated Load Value according to SAE J1979 available on CAN.
    PIIsgModReqA575D1D5BF18E736EB3FDC768E70B1B3
      data IsgModReq: type=IsgModTyp1  # Mode request for ISG motor drive system
    PIUDcReqIntAC13EFA15431536B5B73034C4E3A9C98
      data UDcReqInt: type=UDcInt
    PIIsgTqReqA17F340574CCF2D9426EC3E1BF42934B
      data IsgTqReq: type=PtTqType  # Requested ISG motor torque on the crankshaft. The torque is positive in the forward rotation direction.
    PIEngTA369F8DA2C656E15DF95953DC5DF5F55
      data EngT: type=EngT  # Engine coolant temperature signal group. Includes: - Engine coolant temperature. Resolution 1 degC. - Engine coolant temperature quality factor.
    PIEngCooltInhbFlowAB368AD01AA04308CC6A31C4B6A4CDEC
      data EngCooltInhbFlow: type=CooltInhb  # Inhibitation of non-crucial coolant flow requests. Sent out to inform that the eninge is in heat up phase and that all additional coolant flow will postphone the time when the engine has reached normal operating temperature.
    PIVehMtnStSafeIntAA5408E2E66353F0E400903AA4B73408
      data VehMtnStSafeInt: type=VehMtnStSafe1
    PIHvBattUDynMinLimA4CF911F2C5EEA4CAA8CDD0FB3E6AE92
      data HvBattUDynMinLim: type=HvU1  # The pack voltage low limit of the Hv Battery, dynamically based on cell voltage distribution. At pack voltages below this limit, there is risk for contactor openeing due to too low cell voltage.
    PICoolgFlwA68607185B3F316295E0EA7D9B474C88
      data CoolgFlw: type=CooltLoFlow
    PIEngSpdOfActvDampgIntA338DD8CBEBB8FF49F6E29D8BC113090
      data EngSpdOfActvDampgInt: type=N1
    PITrsmVehSpdIntAE9025AEEFC6C43F52B096DCE648E8B2
      data TrsmVehSpdInt: type=TrsmVehSpd
    PIActvDampgModReqIntA9214B7D241043C53E1C9B8E4812B73E
      data ActvDampgModReqInt: type=WhlMotSysActvDampgModCodSts
    PIPrpsnFbLimnIndcnIntA641C9E80273A6F413C4ECAECEAF8225
      data PrpsnFbLimnIndcnInt: type=UInt4  # The LOS reconfiguration feedback signal from the LOS manager in the vehicle.
    PIIsgImobSecuKeyA9FA3F9A72FF51E0B0F9BBE874419BC9
      data IsgImobSecuKey: type=Rec32ByteU32ReadFlg
    PIRawSnsr1A779227B702E2CC95298F59B9871842D
      data RawSnsr1: type=ImobSnsr  # Raw unfiltered random value from the HW
    PIPwrLossReqA33F6957FC1AC362468416D77E5189DE
      data PwrLossReq: type=PwrInt  # The requested reactive power (extra losses) in the EM. Used when HVDC generative power is limited but the inverter needs to brake the EM with more power.
    PIPwrLossEnadA87A85B72FDE7A925E2F62DE0E3912FE
      data PwrLossEnad: type=OnOff1
    PIPwrDcLimnStsA585606DFBEEC7644352BA984792E3DF
      data PwrDcLimnSts: type=OnOff1  # Indicates if the HVDC power limitation is active or not.
    PIUDcInt2AD7BAFA8FA1B35AC404F413D01ED9A21
      data UDcInt2: type=UDcInt  # HVDC voltage. Needs to be updated at least every 10 ms.
    PIPwrMeclLimnStsAFC545B8966A8D33BD45D7BF71D6D720
      data PwrMeclLimnSts: type=OnOff1
    PITqAvlIntFromPwrMeclLimnA67C7C1042E2D808CCF62C1CA5324947
      data TqAvlIntFromPwrMeclLimn: type=TqRngInt
    PIPwrLossTqAFBF0C1FBA681D1498C6A0A10088ED6D
      data PwrLossTq: type=TqInt  # The extra torque corresponding to the extra losses power request in PwrLossReq.
    PITqAvlIntFromPwrDcLimnA44A5404E5169E40ACC2FA97F3F218EE
      data TqAvlIntFromPwrDcLimn: type=TqRngInt
    PILimnIndcnIntA471D4C41D0FA5E850F8C2EA7F52740F
      data LimnIndcnInt: type=UInt16
    PIDiActvDampgA416CC37F72C37515D1A1B71D7BFCE6B
      data DiActvDampg: type=OnOff1
    PITqAvlIntFromSpdLimnA88762D4BCEEE7C18C05D620D2A53FB7
      data TqAvlIntFromSpdLimn: type=TqRngInt
    PISpdLimnStsAB5F45D2468E8AD67E0549EB46AFBECB
      data SpdLimnSts: type=OnOff1  # Indicates if the EM speed limitation is active or not.
    PIIsgMotCooltFlowReqAC017B6491976CD2C5366BD7CAC36C21
      data IsgMotCooltFlowReq: type=IsgMotCooltFlow  # Flow request for coolant to the CISG
    PICooltTIntABA6C2FB5F9C9F98F11F4E7B47E94BF1
      data CooltTInt: type=TInt  # Measured inlet temperature
    PIIDcIsgAA24CC47A5895D47ED396E1A8097DB93
      data IDcIsg: type=HvI1  # DC current measured in the IGM.
    PIImobEngSts3A6E933882F2A9DABAE3172DA0C0099F9
      data ImobEngSts3: type=ImobSts  # Message from IGM to CEM with immo status. Can be undefined, immobilised, motive mobilised or non motive mobilised.
    PIActvDchaAvlAF45BC8BAD28EC2A3C8040AFDD55349F
      data ActvDchaAvl: type=DchaAvl  # Signal reports availability of active discharge
    PIImobEngChk3A4FBF13F0984B1D3EE06F98D42F3A586
      data ImobEngChk3: type=ImobEngChk  # Message from IGM to CEM that challenge is available and 7 bytes of challenge.
    PIDiAntiSpinAA6A6AB9BA01A6E343E602AC7F92681A
      data DiAntiSpin: type=OnOff1
    PIImobMemReadA91D2DE63661473CA3BED2098AF71AA2
      data ImobMemRead: type=ImobMemSts
    PIImobEngMgrReq3A0CE8CB01E6089ADF34F6C03D6663521
      data ImobEngMgrReq3: type=ImobEngMgrReq  # Command from CEM to IGM with desired immo status and 7 bytes of response
    PIIDcLimnStsAFFC29840C033E7F1057C66074173886
      data IDcLimnSts: type=OnOff1  # Indicates if the HVDC current limitation is active or not.
    PITqAvlIntFromIDcLimnA6AE4458F33E3485DA5C10021B0ED5EF
      data TqAvlIntFromIDcLimn: type=TqRngInt
    PIImobMemWrA9A3884AF4980F091E263CD367E0641E
      data ImobMemWr: type=ImobMemSts
    PISpdActIsgA26AA018462F130C7314E8F20E24E4B3
      data SpdActIsg: type=IsgSpd1  # Actual ISG Speed referred to Crankshaft
    PIInvrTIsgAB199C68BDBFBE871AEDC09AAB2EC77D
      data InvrTIsg: type=T3  # Temperature of the inverter
    PITqAvlOutIntA8FBC11255569863459BE05FB5FB6599
      data TqAvlOutInt: type=TqRngInt  # Available torque signal from all limitations, to be sent on CAN.
    PITqAvlIntFromElecMotTLimnA8D8C44DCAB2C3498F4B4354A447D7C6
      data TqAvlIntFromElecMotTLimn: type=TqRngInt
    PIElecMotTLimnStsA6BEDDE4EB2F86B8B7F66C75F285B97F
      data ElecMotTLimnSts: type=OnOff1  # Indicates if the EM temp limitation is active or not.
    PITqAvlIntFromUDcLimnA426C090B7346303D623FAFF22E09D3B
      data TqAvlIntFromUDcLimn: type=TqRngInt
    PIUDcLimnStsA4D210619C0D9593F04F3DF3143262B6
      data UDcLimnSts: type=OnOff1  # Indicates if the HVDC voltage limitation is active or not.
    PIIDcDcActHiSideACA1BEE452F259EF0E33BB117EFA74DE
      data IDcDcActHiSide: type=HvI1  # Actual measured current on the HV side
    PIVehCfgPrmAE65EF29B86394A6DEA2965D361C5011
      data VehCfgPrm: type=VehCfgPrm  # VehicleConfigurationParameters: Car Config container signal. Values of Car Config parameters #1 - #504 are mapped into 72 blocks. Each block is published in this signal using an 8-byte record: Block counter (MSB) + 7 parameter value byte positions. Block counter runs through all 72 blocks in a sequential loop (normal operation). When transmitted, block 1 will contain current values on Car Config parameters #1 - #7, block 2 -> #8 - #14 ... block 72 -> #498 - #504. Any faulty parameter value is indicated using 255.
    PIFltInfoIsgA7E08B38744AFC00D7019966FBFAF8DC
      data FltInfoIsg: type=HvFltInfo1  # Inverter fault information signal.
    PIDcDcActvdA2A804C0E411403591D0DA528A4C2EFF
      data DcDcActvd: type=DcDcActvd  # DcDc activation signal. While this port is set to "DcDcActvd_ConversionToLVSide" the DcDc shall start converting power to the Low side
    PIBkpOfDstTrvldAA7558D503B82DD1C431D477B9209E63
      data BkpOfDstTrvld: type=Len31  # Indicated odometer (total driven distance) value in km.
    PIPwrLvlElecA99BD44446985C19F88B43341DB74BC7
      data PwrLvlElec: type=LvlElecSts1  # Describes the main states, the main byte, of electric power level in the vehicle: See REQ 343561 (Low voltage energy and power management) for a table that explains states.
    PIVehBattUA5AB3008FF93CF56E6015EAB6A52B5DE
      data VehBattU: type=SysU  # Present vehicle voltage measured by CEM with QF. QF values: 3: Value Reliable 2: Value from back up sensor 1: Init 0: Value not reliable
    PIIsgTqActADB3B00C7937D1F897CBAD68E49083CB
      data IsgTqAct: type=IsgTqActSafe1  # Estimated ISG motor torque on the crankshaft. The torque is positive in the forward rotation direction.
    PIPrpsnCntrForMissComADBEFCEF89E3FB12564498BFE6B58D9A
      data PrpsnCntrForMissCom: type=UInt8
    PIMstCfgIDPropulsionCANA43F01261265E9B4196B2461CF6DBAD8
      data MstCfgIDPropulsionCAN: type=UInt16
    PIIniValSigCfgIDPropulsionCANA60F488426CA723C7898718C099DD02C
      data IniValSigCfgIDPropulsionCAN: type=UInt16
    PITqAvlIsgA0AE1CCE074524FCCEBFA00A69889FF6
      data TqAvlIsg: type=IsgTqAvl  # Maximum available ISG motor torque on the crankshaft. A function of motor drive system HW Limits, actual DC Voltage, motor temperature, etc. The torque is positive in the forward rotation direction. Minimum available ISG motor torque on the crankshaft. A function of motor drive system HW Limits, actual DC Voltage, motor temperature, etc. The torque is positive in the forward rotation direction.
    PILimnIndcnDcDcAFA63C2417E8A681AB5D0573B3EFF44A
      data LimnIndcnDcDc: type=LimnIndcnDcDc  # Indication signal from the DcDc that tells that a DTC is set
    PIFltElecDcDcAFD84EB0989B0A5D7176A63628E1ED74
      data FltElecDcDc: type=DevErrSts2  # Fault signal for DcDc. If a electrical fault is present in the DcDc, this signal is set to "Flt", otherwise "NoFlt"
    PIPwrDcDcAvlA0330DAA85C31A2692F87A90896697E7
      data PwrDcDcAvl: type=Pwr3  # The amount of power available for the DCDC.
    PITDcDcA0D6338BB3C5B7F9C454AE38B2D9ED20
      data TDcDc: type=HvT1  # DCDC temperature
    PIFltDcDcAA68F75B8142F4211A964DCC6C977A50
      data FltDcDc: type=DevErrSts2  # Fault signal for DcDc. If a temperaturel fault is present in the DcDc, this signal is set to "Flt", otherwise "NoFlt"
    PIHvConvPwrAllwdA746C45F553BF198868447F6A309DB37
      data HvConvPwrAllwd: type=Pwr3  # Power limitation for DC/DC converter (i.e. sets a limit for power consumption for 12V system).
    PIUDcDcActHiSideAF3F8A46A8DDF4C9C21D8B7214BF7841
      data UDcDcActHiSide: type=HvU1  # Measured voltage on the HV side
package /Constants
  30 x constant specification:
    A566A6590FA167C633F64C4171ADCCB7: value-spec=0.0
    A2AB2663EDCB674997EFCB4941EAE573: value-spec=0
    ACF963A02DED26B3921E3180925CE8A3: value-spec=fields=[UsgModSts:1, CarModSts1:0, CarModSubtypWdCarModSubtyp:0, EgyLvlElecMai:0, EgyLvlElecSubtyp:0, PwrLvlElecMai:0, PwrLvlElecSubtyp:0, FltEgyCnsWdSts:0, Chks:0, Cntr:0]
    A6F8BF8DB078858B4AABFD332A9D9219: value-spec=10.6
    A636F88E591B4F4A2849AD5E95838F02: value-spec=5
    A98E5C9C409339ACD044027A1055A07E: value-spec=fields=[IsgTqAllwdChks:0.0, IsgTqAllwdCntr:0.0, IsgTqAllwd:0]
    AD30053758475D867C29EE0F5723584A: value-spec=1
    A5E6433C0EBBF7A278234C60E9932635: value-spec=3
    A8CFFE3621C1DA13E6FF691AE3A9D3C1: value-spec=fields=[Min:-50000.0, Max:50000.0]
    AE6F9FB492BDC7FCA4CAB2BF64648C6A: value-spec=2
    A6571BE8D08FA8624FE034351C65BBB8: value-spec=fields=[Min:0.0, Max:0.0]
    A1AD216C2FE294940F0F0050DE621F46: value-spec=fields=[EngN:0.0, EngNGrdt:0.0, EngNChks:0, EngNCntr:0]
    AD7F32376661EA365B8999AB28B9293D: value-spec=fields=[EngT:0.0, EngTQf:0]
    AB2213CC11E3B1591DBD2F09CF632E62: value-spec=fields=[PtTqAtAxleReMinReq:0.0, PtTqAtAxleReMinReqChks:0, PtTqAtAxleReMinReqCntr:0]
    A68FE985916865C70A611D0FFC6B9CF2: value-spec=fields=[VehSpdLgt:0.0, VehSpdLgtQf:0, VehSpdLgtCntr:0, VehSpdLgtChks:0]
    AFC8E6EC384951247C75A8CAF348B75E: value-spec=fields=[VehMtnSt:1, VehMtnStChks:0, VehMtnStCntr:0]
    AA9EE529BC7CE8EA3A0A158775B5EB0F: value-spec=fields=[MemReadFlg:0, Byte00To03:0, Byte04To07:0, Byte08To11:0, Byte12To15:0, Byte16To19:0, Byte20To23:0, Byte24To27:0, Byte28To31:0]
    A978A77034898F3865BDF257EAEB987B: value-spec=fields=[ImobEngChkSts:0, ImobEngDataChk0:0, ImobEngDataChk1:0, ImobEngDataChk2:0, ImobEngDataChk3:0, ImobEngDataChk4:0, ImobEngDataChk5:0, ImobEngDataChk6:0]
    A2DE60DBB38156AAEB7CD85B81802804: value-spec=fields=[ImobEngMgrCmdTar1:0, ImobEngDataMgrReq0:0, ImobEngDataMgrReq1:0, ImobEngDataMgrReq2:0, ImobEngDataMgrReq3:0, ImobEngDataMgrReq4:0, ImobEngDataMgrReq5:0, ImobEngDataMgrReq6:0]
    A475F4F393542C3A8168E5F3043367CB: value-spec=fields=[Min:0.0, Max:500.0]
    A6B6B7AFC37B54D73A25C7304F41930B: value-spec=fields=[BlkIDBytePosn1:0.0, CCPBytePosn2:0.0, CCPBytePosn3:0.0, CCPBytePosn4:0.0, CCPBytePosn5:0.0, CCPBytePosn6:0.0, CCPBytePosn7:0.0, CCPBytePosn8:0.0]
    A57ED80A599FA7B04B45D8F7A2186272: value-spec=fields=[SysU:0.0, SysUQf:1]
    ACF2B721822169C938BBC6AFE39038B4: value-spec=fields=[MemReadFlg:1, Byte00To03:0, Byte04To07:0, Byte08To11:0, Byte12To15:0, Byte16To19:0, Byte20To23:0, Byte24To27:0, Byte28To31:0]
    A61DABA1FBDC405A667816EC215554EE: value-spec=100.0
    AF379A41000B10CC950AE01255929993: value-spec=fields=[Cntr:0, Chks:0, IsgTqAct:0.0, QualityFactor:0]
    A2353A48319CC311B10A39C1A8CCC3AA: value-spec=400.0
    A24B0BD917EA440C0F346C489758B0D2: value-spec=fields=[Min:50000.0, Max:50000.0]
    ADB0659449328ECFB4D14A1C7B2086CD: value-spec=fields=[ImobEngChkSts:1, ImobEngDataChk0:0, ImobEngDataChk1:0, ImobEngDataChk2:0, ImobEngDataChk3:0, ImobEngDataChk4:0, ImobEngDataChk5:0, ImobEngDataChk6:0]
    A33A01312D59D0946C249E45DA6690C6: value-spec=fields=[IsgTqAvlMax:0.0, IsgTqAvlMin:0.0]
    A32713970D3B0BFBCDB5A6CFD6484D49: value-spec=20460.0
package /ComponentType/IvtrCoolgCtrl/IvtrCoolgCtrlMAIN
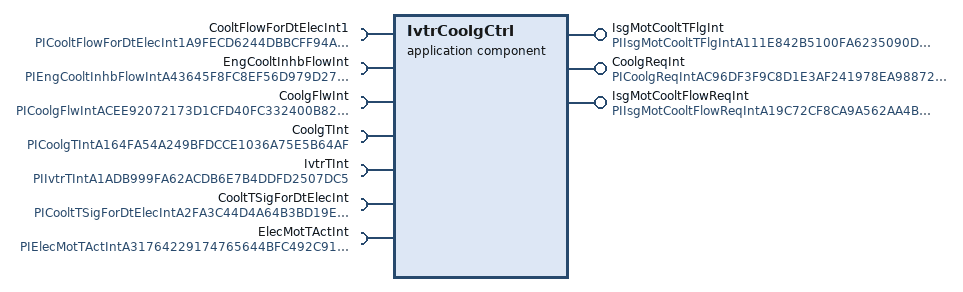
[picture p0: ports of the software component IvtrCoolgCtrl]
  application sw component type IvtrCoolgCtrl
    4 x require port:
      CooltFlowForDtElecInt1: nonqueued-receiver-com-spec{data-element=CooltFlowForDtElecInt1, init-value=constant-reference=A566A6590FA167C633F64C4171ADCCB7}, required-interface=PICooltFlowForDtElecInt1A9FECD6244DBBCFF94A4D3481557ACF8
      EngCooltInhbFlowInt: nonqueued-receiver-com-spec{data-element=EngCooltInhbFlowInt, init-value=constant-reference=A2AB2663EDCB674997EFCB4941EAE573}, required-interface=PIEngCooltInhbFlowIntA43645F8FC8EF56D979D27462C05E480
      CoolgFlwInt: nonqueued-receiver-com-spec{data-element=CoolgFlwInt, init-value=constant-reference=A566A6590FA167C633F64C4171ADCCB7}, required-interface=PICoolgFlwIntACEE92072173D1CFD40FC332400B8271
      CoolgTInt: nonqueued-receiver-com-spec{data-element=CoolgTInt, init-value=constant-reference=A566A6590FA167C633F64C4171ADCCB7}, required-interface=PICoolgTIntA164FA54A249BFDCCE1036A75E5B64AF
    provide port IsgMotCooltTFlgInt: nonqueued-sender-com-spec{data-element=IsgMotCooltTFlgInt, init-value=constant-reference=AD30053758475D867C29EE0F5723584A}, provided-interface=PIIsgMotCooltTFlgIntA111E842B5100FA6235090DA6780D515
    provide port CoolgReqInt: nonqueued-sender-com-spec{data-element=CoolgReqInt, init-value=constant-reference=A5E6433C0EBBF7A278234C60E9932635}, provided-interface=PICoolgReqIntAC96DF3F9C8D1E3AF241978EA9887249
    require port IvtrTInt: nonqueued-receiver-com-spec{data-element=IvtrTInt, init-value=constant-reference=A566A6590FA167C633F64C4171ADCCB7}, required-interface=PIIvtrTIntA1ADB999FA62ACDB6E7B4DDFD2507DC5
    provide port IsgMotCooltFlowReqInt: nonqueued-sender-com-spec{data-element=IsgMotCooltFlowReqInt, init-value=constant-reference=A566A6590FA167C633F64C4171ADCCB7}, provided-interface=PIIsgMotCooltFlowReqIntA19C72CF8CA9A562AA4BC89712FF8931
    require port CooltTSigForDtElecInt: nonqueued-receiver-com-spec{data-element=CooltTSigForDtElecInt, init-value=constant-reference=A566A6590FA167C633F64C4171ADCCB7}, required-interface=PICooltTSigForDtElecIntA2FA3C44D4A64B3BD19E1FAA3F5036C0
    require port ElecMotTActInt: nonqueued-receiver-com-spec{data-element=ElecMotTActInt, init-value=constant-reference=A566A6590FA167C633F64C4171ADCCB7}, required-interface=PIElecMotTActIntA31764229174765644BFC492C91799B4
    behavior BEcfea32ef1645ed912d21c017cce545: handle-termination-and-restart=NO-SUPPORT
      port-api-options:
        enable-take-address=false, indirect-api=false, port=IvtrCoolgCtrl/CooltFlowForDtElecInt1
        enable-take-address=false, indirect-api=false, port=EngCooltInhbFlowInt
        enable-take-address=false, indirect-api=false, port=CoolgFlwInt
        enable-take-address=false, indirect-api=false, port=CoolgTInt
        enable-take-address=false, indirect-api=false, port=IsgMotCooltTFlgInt
        enable-take-address=false, indirect-api=false, port=CoolgReqInt
        enable-take-address=false, indirect-api=false, port=IvtrCoolgCtrl/IvtrTInt
        enable-take-address=false, indirect-api=false, port=IsgMotCooltFlowReqInt
        enable-take-address=false, indirect-api=false, port=IvtrCoolgCtrl/CooltTSigForDtElecInt
        enable-take-address=false, indirect-api=false, port=IvtrCoolgCtrl/ElecMotTActInt
package /ComponentType/IvtrTqArbMgrSlow/IvtrTqArbMgrSlowMAIN
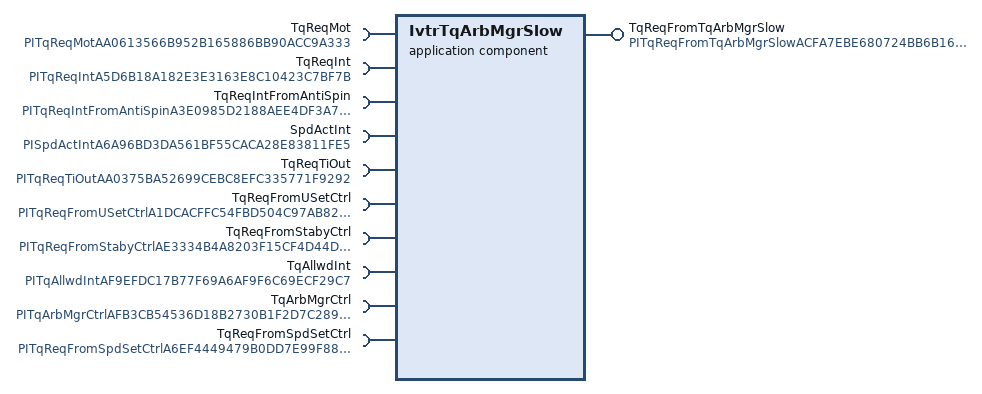
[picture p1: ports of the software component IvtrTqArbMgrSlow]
  application sw component type IvtrTqArbMgrSlow
    6 x require port:
      TqReqMot: nonqueued-receiver-com-spec{data-element=TqReqMot, init-value=constant-reference=A566A6590FA167C633F64C4171ADCCB7}, required-interface=PITqReqMotAA0613566B952B165886BB90ACC9A333
      TqReqInt: nonqueued-receiver-com-spec{data-element=TqReqInt, init-value=constant-reference=A566A6590FA167C633F64C4171ADCCB7}, required-interface=PITqReqIntA5D6B18A182E3E3163E8C10423C7BF7B
      TqReqIntFromAntiSpin: nonqueued-receiver-com-spec{data-element=TqReqIntFromAntiSpin, init-value=constant-reference=A566A6590FA167C633F64C4171ADCCB7}, required-interface=PITqReqIntFromAntiSpinA3E0985D2188AEE4DF3A78C4373D692A
      SpdActInt: nonqueued-receiver-com-spec{data-element=SpdActInt, init-value=constant-reference=A566A6590FA167C633F64C4171ADCCB7}, required-interface=PISpdActIntA6A96BD3DA561BF55CACA28E83811FE5
      TqReqTiOut: nonqueued-receiver-com-spec{data-element=TqReqTiOut, init-value=constant-reference=A2AB2663EDCB674997EFCB4941EAE573}, required-interface=PITqReqTiOutAA0375BA52699CEBC8EFC335771F9292
      TqReqFromUSetCtrl: nonqueued-receiver-com-spec{data-element=TqReqFromUSetCtrl, init-value=constant-reference=A566A6590FA167C633F64C4171ADCCB7}, required-interface=PITqReqFromUSetCtrlA1DCACFFC54FBD504C97AB823DEC438C
    provide port TqReqFromTqArbMgrSlow: nonqueued-sender-com-spec{data-element=TqReqFromTqArbMgrSlow, init-value=constant-reference=A566A6590FA167C633F64C4171ADCCB7}, provided-interface=PITqReqFromTqArbMgrSlowACFA7EBE680724BB6B16A7641540B266
    4 x require port:
      TqReqFromStabyCtrl: nonqueued-receiver-com-spec{data-element=TqReqFromStabyCtrl, init-value=constant-reference=A566A6590FA167C633F64C4171ADCCB7}, required-interface=PITqReqFromStabyCtrlAE3334B4A8203F15CF4D44D6347AB2D9
      TqAllwdInt: nonqueued-receiver-com-spec{data-element=TqAllwdInt, init-value=constant-reference=A5E6433C0EBBF7A278234C60E9932635}, required-interface=PITqAllwdIntAF9EFDC17B77F69A6AF9F6C69ECF29C7
      TqArbMgrCtrl: nonqueued-receiver-com-spec{data-element=TqArbMgrCtrl, init-value=constant-reference=A2AB2663EDCB674997EFCB4941EAE573}, required-interface=PITqArbMgrCtrlAFB3CB54536D18B2730B1F2D7C289A9B
      TqReqFromSpdSetCtrl: nonqueued-receiver-com-spec{data-element=TqReqFromSpdSetCtrl, init-value=constant-reference=A566A6590FA167C633F64C4171ADCCB7}, required-interface=PITqReqFromSpdSetCtrlA6EF4449479B0DD7E99F884852E50B53
    behavior BEf5a9acc4da44f9b7a47b9ace39a4bb: handle-termination-and-restart=NO-SUPPORT
      port-api-options:
        enable-take-address=false, indirect-api=false, port=IvtrTqArbMgrSlow/TqReqMot
        enable-take-address=false, indirect-api=false, port=IvtrTqArbMgrSlow/TqReqInt
        enable-take-address=false, indirect-api=false, port=TqReqIntFromAntiSpin
        enable-take-address=false, indirect-api=false, port=IvtrTqArbMgrSlow/SpdActInt
        enable-take-address=false, indirect-api=false, port=IvtrTqArbMgrSlow/TqReqTiOut
        enable-take-address=false, indirect-api=false, port=TqReqFromUSetCtrl
        enable-take-address=false, indirect-api=false, port=TqReqFromTqArbMgrSlow
        enable-take-address=false, indirect-api=false, port=TqReqFromStabyCtrl
        enable-take-address=false, indirect-api=false, port=IvtrTqArbMgrSlow/TqAllwdInt
        enable-take-address=false, indirect-api=false, port=TqArbMgrCtrl
        enable-take-address=false, indirect-api=false, port=TqReqFromSpdSetCtrl
package /ComponentType/IvtrModMgr/IvtrModMgrMAIN
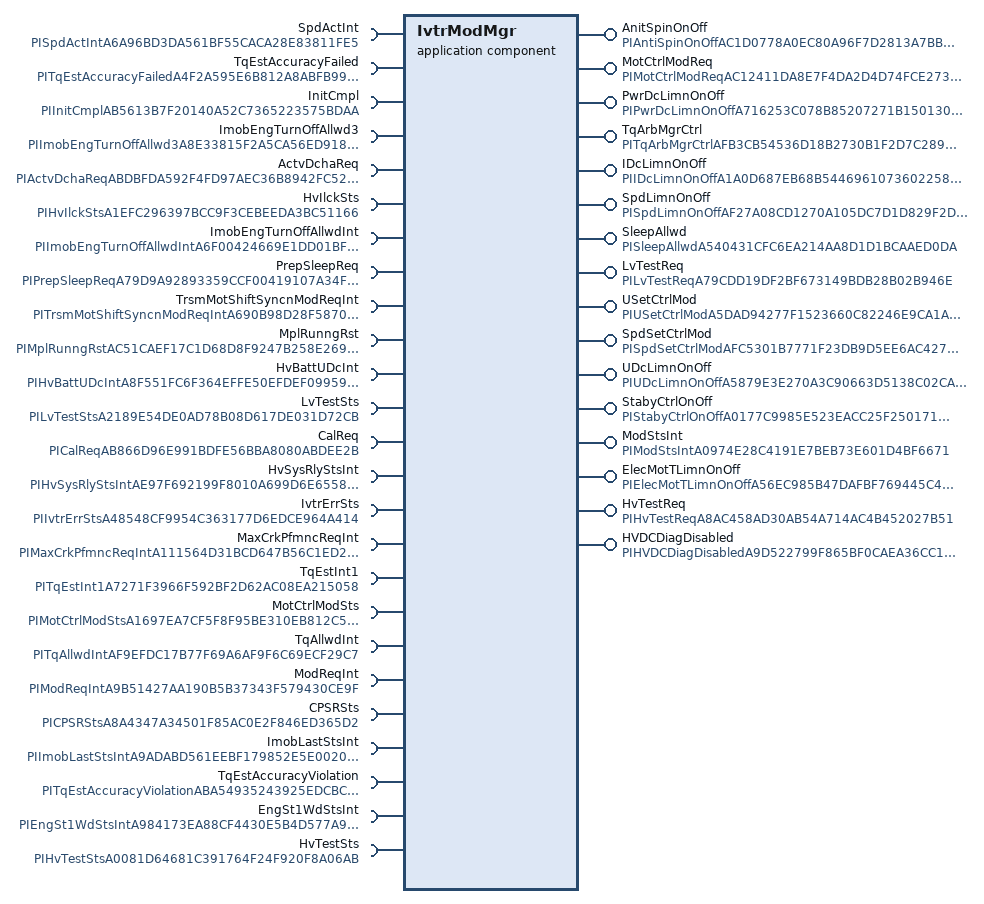
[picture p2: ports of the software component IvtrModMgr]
  application sw component type IvtrModMgr
    require port SpdActInt: nonqueued-receiver-com-spec{data-element=SpdActInt, init-value=constant-reference=A566A6590FA167C633F64C4171ADCCB7}, required-interface=PISpdActIntA6A96BD3DA561BF55CACA28E83811FE5
    provide port AnitSpinOnOff: nonqueued-sender-com-spec{data-element=AntiSpinOnOff, init-value=constant-reference=A2AB2663EDCB674997EFCB4941EAE573}, provided-interface=PIAntiSpinOnOffAC1D0778A0EC80A96F7D2813A7BB259C
    require port TqEstAccuracyFailed: nonqueued-receiver-com-spec{data-element=TqEstAccuracyFailed, init-value=constant-reference=A2AB2663EDCB674997EFCB4941EAE573}, required-interface=PITqEstAccuracyFailedA4F2A595E6B812A8ABFB998FFD3DDAAF
    provide port MotCtrlModReq: nonqueued-sender-com-spec{data-element=MotCtrlModReq, init-value=constant-reference=A2AB2663EDCB674997EFCB4941EAE573}, provided-interface=PIMotCtrlModReqAC12411DA8E7F4DA2D4D74FCE273A6CD
    require port InitCmpl: nonqueued-receiver-com-spec{data-element=InitCmpl, init-value=constant-reference=A2AB2663EDCB674997EFCB4941EAE573}, required-interface=PIInitCmplAB5613B7F20140A52C7365223575BDAA
    provide port PwrDcLimnOnOff: nonqueued-sender-com-spec{data-element=PwrDcLimnOnOff, init-value=constant-reference=A2AB2663EDCB674997EFCB4941EAE573}, provided-interface=PIPwrDcLimnOnOffA716253C078B85207271B150130ACE4C
    require port ImobEngTurnOffAllwd3: nonqueued-receiver-com-spec{data-element=ImobEngTurnOffAllwd3, init-value=constant-reference=A2AB2663EDCB674997EFCB4941EAE573}, required-interface=PIImobEngTurnOffAllwd3A8E33815F2A5CA56ED918D0B41C26BA7
    provide port TqArbMgrCtrl: nonqueued-sender-com-spec{data-element=TqArbMgrCtrl, init-value=constant-reference=A2AB2663EDCB674997EFCB4941EAE573}, provided-interface=PITqArbMgrCtrlAFB3CB54536D18B2730B1F2D7C289A9B
    provide port IDcLimnOnOff: nonqueued-sender-com-spec{data-element=IDcLimnOnOff, init-value=constant-reference=A2AB2663EDCB674997EFCB4941EAE573}, provided-interface=PIIDcLimnOnOffA1A0D687EB68B5446961073602258F9F
    provide port SpdLimnOnOff: nonqueued-sender-com-spec{data-element=SpdLimnOnOff, init-value=constant-reference=A2AB2663EDCB674997EFCB4941EAE573}, provided-interface=PISpdLimnOnOffAF27A08CD1270A105DC7D1D829F2DFFC
    5 x require port:
      ActvDchaReq: nonqueued-receiver-com-spec{data-element=ActvDchaReq, init-value=constant-reference=A2AB2663EDCB674997EFCB4941EAE573}, required-interface=PIActvDchaReqABDBFDA592F4FD97AEC36B8942FC52D1
      HvIlckSts: nonqueued-receiver-com-spec{data-element=HvIlckSts, init-value=constant-reference=AD30053758475D867C29EE0F5723584A}, required-interface=PIHvIlckStsA1EFC296397BCC9F3CEBEEDA3BC51166
      ImobEngTurnOffAllwdInt: nonqueued-receiver-com-spec{data-element=ImobEngTurnOffAllwdInt, init-value=constant-reference=A2AB2663EDCB674997EFCB4941EAE573}, required-interface=PIImobEngTurnOffAllwdIntA6F00424669E1DD01BF13F084E9A5B01
      PrepSleepReq: nonqueued-receiver-com-spec{data-element=PrepSleepReq, init-value=constant-reference=A2AB2663EDCB674997EFCB4941EAE573}, required-interface=PIPrepSleepReqA79D9A92893359CCF00419107A34F584
      TrsmMotShiftSyncnModReqInt: nonqueued-receiver-com-spec{data-element=TrsmMotShiftSyncnModReqInt, init-value=constant-reference=A2AB2663EDCB674997EFCB4941EAE573}, required-interface=PITrsmMotShiftSyncnModReqIntA690B98D28F58708C7741593A47EC6F4
    provide port SleepAllwd: nonqueued-sender-com-spec{data-element=SleepAllwd, init-value=constant-reference=A2AB2663EDCB674997EFCB4941EAE573}, provided-interface=PISleepAllwdA540431CFC6EA214AA8D1D1BCAAED0DA
    require port MplRunngRst: nonqueued-receiver-com-spec{data-element=MplRunngRst, init-value=constant-reference=A2AB2663EDCB674997EFCB4941EAE573}, required-interface=PIMplRunngRstAC51CAEF17C1D68D8F9247B258E26918
    provide port LvTestReq: nonqueued-sender-com-spec{data-element=LvTestReq, init-value=constant-reference=A2AB2663EDCB674997EFCB4941EAE573}, provided-interface=PILvTestReqA79CDD19DF2BF673149BDB28B02B946E
    require port HvBattUDcInt: nonqueued-receiver-com-spec{data-element=HvBattUDcInt, init-value=constant-reference=A566A6590FA167C633F64C4171ADCCB7}, required-interface=PIHvBattUDcIntA8F551FC6F364EFFE50EFDEF09959371
    require port LvTestSts: nonqueued-receiver-com-spec{data-element=LvTestSts, init-value=constant-reference=A2AB2663EDCB674997EFCB4941EAE573}, required-interface=PILvTestStsA2189E54DE0AD78B08D617DE031D72CB
    provide port USetCtrlMod: nonqueued-sender-com-spec{data-element=USetCtrlMod, init-value=constant-reference=A2AB2663EDCB674997EFCB4941EAE573}, provided-interface=PIUSetCtrlModA5DAD94277F1523660C82246E9CA1AEB
    provide port SpdSetCtrlMod: nonqueued-sender-com-spec{data-element=SpdSetCtrlMod, init-value=constant-reference=A2AB2663EDCB674997EFCB4941EAE573}, provided-interface=PISpdSetCtrlModAFC5301B7771F23DB9D5EE6AC427D0DF
    5 x require port:
      CalReq: nonqueued-receiver-com-spec{data-element=CalReq, init-value=constant-reference=A2AB2663EDCB674997EFCB4941EAE573}, required-interface=PICalReqAB866D96E991BDFE56BBA8080ABDEE2B
      HvSysRlyStsInt: nonqueued-receiver-com-spec{data-element=HvSysRlyStsInt, init-value=constant-reference=A2AB2663EDCB674997EFCB4941EAE573}, required-interface=PIHvSysRlyStsIntAE97F692199F8010A699D6E6558D46BB
      IvtrErrSts: nonqueued-receiver-com-spec{data-element=IvtrErrSts, init-value=constant-reference=A2AB2663EDCB674997EFCB4941EAE573}, required-interface=PIIvtrErrStsA48548CF9954C363177D6EDCE964A414
      MaxCrkPfmncReqInt: nonqueued-receiver-com-spec{data-element=MaxCrkPfmncReqInt, init-value=constant-reference=A2AB2663EDCB674997EFCB4941EAE573}, required-interface=PIMaxCrkPfmncReqIntA111564D31BCD647B56C1ED2AC778042
      TqEstInt1: nonqueued-receiver-com-spec{data-element=TqEstInt1, init-value=constant-reference=A566A6590FA167C633F64C4171ADCCB7}, required-interface=PITqEstInt1A7271F3966F592BF2D62AC08EA215058
    4 x provide port:
      UDcLimnOnOff: nonqueued-sender-com-spec{data-element=UDcLimnOnOff, init-value=constant-reference=A2AB2663EDCB674997EFCB4941EAE573}, provided-interface=PIUDcLimnOnOffA5879E3E270A3C90663D5138C02CA256
      StabyCtrlOnOff: nonqueued-sender-com-spec{data-element=StabyCtrlOnOff, init-value=constant-reference=A2AB2663EDCB674997EFCB4941EAE573}, provided-interface=PIStabyCtrlOnOffA0177C9985E523EACC25F2501718EFA6
      ModStsInt: nonqueued-sender-com-spec{data-element=ModStsInt, init-value=constant-reference=A2AB2663EDCB674997EFCB4941EAE573}, provided-interface=PIModStsIntA0974E28C4191E7BEB73E601D4BF6671
      ElecMotTLimnOnOff: nonqueued-sender-com-spec{data-element=ElecMotTLimnOnOff, init-value=constant-reference=A2AB2663EDCB674997EFCB4941EAE573}, provided-interface=PIElecMotTLimnOnOffA56EC985B47DAFBF769445C481FDAB70
    6 x require port:
      MotCtrlModSts: nonqueued-receiver-com-spec{data-element=MotCtrlModSts, init-value=constant-reference=A2AB2663EDCB674997EFCB4941EAE573}, required-interface=PIMotCtrlModStsA1697EA7CF5F8F95BE310EB812C577CA
      TqAllwdInt: nonqueued-receiver-com-spec{data-element=TqAllwdInt, init-value=constant-reference=A5E6433C0EBBF7A278234C60E9932635}, required-interface=PITqAllwdIntAF9EFDC17B77F69A6AF9F6C69ECF29C7
      ModReqInt: nonqueued-receiver-com-spec{data-element=ModReqInt, init-value=constant-reference=A5E6433C0EBBF7A278234C60E9932635}, required-interface=PIModReqIntA9B51427AA190B5B37343F579430CE9F
      CPSRSts: nonqueued-receiver-com-spec{data-element=CPSRSts, init-value=constant-reference=A2AB2663EDCB674997EFCB4941EAE573}, required-interface=PICPSRStsA8A4347A34501F85AC0E2F846ED365D2
      ImobLastStsInt: nonqueued-receiver-com-spec{data-element=ImobLastStsInt, init-value=constant-reference=AE6F9FB492BDC7FCA4CAB2BF64648C6A}, required-interface=PIImobLastStsIntA9ADABD561EEBF179852E5E0020F68FB
      TqEstAccuracyViolation: nonqueued-receiver-com-spec{data-element=TqEstAccuracyViolation, init-value=constant-reference=A2AB2663EDCB674997EFCB4941EAE573}, required-interface=PITqEstAccuracyViolationABA54935243925EDCBC2DC8B5C54F204
    provide port HvTestReq: nonqueued-sender-com-spec{data-element=HvTestReq, init-value=constant-reference=A2AB2663EDCB674997EFCB4941EAE573}, provided-interface=PIHvTestReqA8AC458AD30AB54A714AC4B452027B51
    require port EngSt1WdStsInt: nonqueued-receiver-com-spec{data-element=EngSt1WdStsInt, init-value=constant-reference=A636F88E591B4F4A2849AD5E95838F02}, required-interface=PIEngSt1WdStsIntA984173EA88CF4430E5B4D577A9BEE8A
    provide port HVDCDiagDisabled: nonqueued-sender-com-spec{data-element=HVDCDiagDisabled, init-value=constant-reference=AD30053758475D867C29EE0F5723584A}, provided-interface=PIHVDCDiagDisabledA9D522799F865BF0CAEA36CC194489F7
    require port HvTestSts: nonqueued-receiver-com-spec{data-element=HvTestSts, init-value=constant-reference=A2AB2663EDCB674997EFCB4941EAE573}, required-interface=PIHvTestStsA0081D64681C391764F24F920F8A06AB
    behavior BE88f87b366a4ad281fb95eabc93df72: handle-termination-and-restart=NO-SUPPORT
      port-api-options:
        enable-take-address=false, indirect-api=false, port=IvtrModMgr/SpdActInt
        enable-take-address=false, indirect-api=false, port=AnitSpinOnOff
        enable-take-address=false, indirect-api=false, port=IvtrModMgr/TqEstAccuracyFailed
        enable-take-address=false, indirect-api=false, port=IvtrModMgr/MotCtrlModReq
        enable-take-address=false, indirect-api=false, port=IvtrModMgr/InitCmpl
        enable-take-address=false, indirect-api=false, port=PwrDcLimnOnOff
        enable-take-address=false, indirect-api=false, port=IvtrModMgr/ImobEngTurnOffAllwd3
        enable-take-address=false, indirect-api=false, port=TqArbMgrCtrl
        enable-take-address=false, indirect-api=false, port=IDcLimnOnOff
        enable-take-address=false, indirect-api=false, port=SpdLimnOnOff
        enable-take-address=false, indirect-api=false, port=ActvDchaReq
        enable-take-address=false, indirect-api=false, port=IvtrModMgr/HvIlckSts
        enable-take-address=false, indirect-api=false, port=ImobEngTurnOffAllwdInt
        enable-take-address=false, indirect-api=false, port=IvtrModMgr/PrepSleepReq
        enable-take-address=false, indirect-api=false, port=TrsmMotShiftSyncnModReqInt
        enable-take-address=false, indirect-api=false, port=IvtrModMgr/SleepAllwd
        enable-take-address=false, indirect-api=false, port=IvtrModMgr/MplRunngRst
        enable-take-address=false, indirect-api=false, port=IvtrModMgr/LvTestReq
        enable-take-address=false, indirect-api=false, port=IvtrModMgr/HvBattUDcInt
        enable-take-address=false, indirect-api=false, port=IvtrModMgr/LvTestSts
        enable-take-address=false, indirect-api=false, port=USetCtrlMod
        enable-take-address=false, indirect-api=false, port=SpdSetCtrlMod
        enable-take-address=false, indirect-api=false, port=IvtrModMgr/CalReq
        enable-take-address=false, indirect-api=false, port=IvtrModMgr/HvSysRlyStsInt
        enable-take-address=false, indirect-api=false, port=IvtrModMgr/IvtrErrSts
        enable-take-address=false, indirect-api=false, port=MaxCrkPfmncReqInt
        enable-take-address=false, indirect-api=false, port=IvtrModMgr/TqEstInt1
        enable-take-address=false, indirect-api=false, port=UDcLimnOnOff
        enable-take-address=false, indirect-api=false, port=StabyCtrlOnOff
        enable-take-address=false, indirect-api=false, port=ModStsInt
        enable-take-address=false, indirect-api=false, port=ElecMotTLimnOnOff
        enable-take-address=false, indirect-api=false, port=IvtrModMgr/MotCtrlModSts
        enable-take-address=false, indirect-api=false, port=IvtrModMgr/TqAllwdInt
        enable-take-address=false, indirect-api=false, port=ModReqInt
        enable-take-address=false, indirect-api=false, port=IvtrModMgr/CPSRSts
        enable-take-address=false, indirect-api=false, port=ImobLastStsInt
        enable-take-address=false, indirect-api=false, port=IvtrModMgr/TqEstAccuracyViolation
        enable-take-address=false, indirect-api=false, port=IvtrModMgr/HvTestReq
        enable-take-address=false, indirect-api=false, port=IvtrModMgr/EngSt1WdStsInt
        enable-take-address=false, indirect-api=false, port=IvtrModMgr/HVDCDiagDisabled
        enable-take-address=false, indirect-api=false, port=IvtrModMgr/HvTestSts
package /ComponentType/IvtrOnBdDiagcComDi/IvtrOnBdDiagcComDiMAIN
  application sw component type IvtrOnBdDiagcComDi
    require port DeactvtTextComInt: nonqueued-receiver-com-spec{data-element=DeactvtTextComInt, init-value=constant-reference=AD30053758475D867C29EE0F5723584A}, required-interface=PIDeactvtTextComIntA412C5C4188DBD312EBDD4AACDF5606F
    behavior BE867caaa68e48589974e775a5faf62b: handle-termination-and-restart=NO-SUPPORT, port-api-option{enable-take-address=false, indirect-api=false, port=DeactvtTextComInt}
package /ComponentType/IvtrTqArbMgrFast/IvtrTqArbMgrFastMAIN
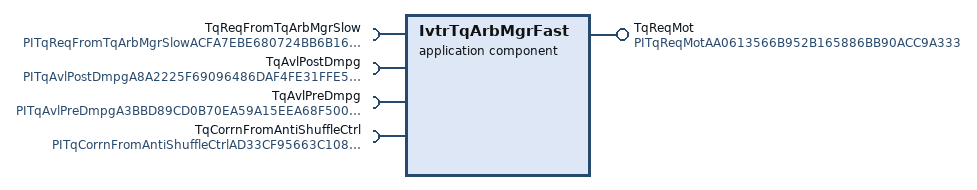
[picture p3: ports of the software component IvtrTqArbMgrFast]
  application sw component type IvtrTqArbMgrFast
    provide port TqReqMot: nonqueued-sender-com-spec{data-element=TqReqMot, init-value=constant-reference=A566A6590FA167C633F64C4171ADCCB7}, provided-interface=PITqReqMotAA0613566B952B165886BB90ACC9A333
    4 x require port:
      TqReqFromTqArbMgrSlow: nonqueued-receiver-com-spec{data-element=TqReqFromTqArbMgrSlow, init-value=constant-reference=A566A6590FA167C633F64C4171ADCCB7}, required-interface=PITqReqFromTqArbMgrSlowACFA7EBE680724BB6B16A7641540B266
      TqAvlPostDmpg: nonqueued-receiver-com-spec{data-element=TqAvlPostDmpg, init-value=constant-reference=A6571BE8D08FA8624FE034351C65BBB8}, required-interface=PITqAvlPostDmpgA8A2225F69096486DAF4FE31FFE52A89
      TqAvlPreDmpg: nonqueued-receiver-com-spec{data-element=TqAvlPreDmpg, init-value=constant-reference=A6571BE8D08FA8624FE034351C65BBB8}, required-interface=PITqAvlPreDmpgA3BBD89CD0B70EA59A15EEA68F5001F0
      TqCorrnFromAntiShuffleCtrl: nonqueued-receiver-com-spec{data-element=TqCorrnFromAntiShuffleCtrl, init-value=constant-reference=A566A6590FA167C633F64C4171ADCCB7}, required-interface=PITqCorrnFromAntiShuffleCtrlAD33CF95663C108692593B0CC185952D
    behavior BE6500b6afcd40d3bb2adad05c1f0475: handle-termination-and-restart=NO-SUPPORT
      port-api-options:
        enable-take-address=false, indirect-api=false, port=IvtrTqArbMgrFast/TqReqMot
        enable-take-address=false, indirect-api=false, port=IvtrTqArbMgrFast/TqReqFromTqArbMgrSlow
        enable-take-address=false, indirect-api=false, port=TqAvlPostDmpg
        enable-take-address=false, indirect-api=false, port=TqAvlPreDmpg
        enable-take-address=false, indirect-api=false, port=TqCorrnFromAntiShuffleCtrl
package /ComponentType/CMACIDDIfCptIn/CMACIDDIfCptInMAIN
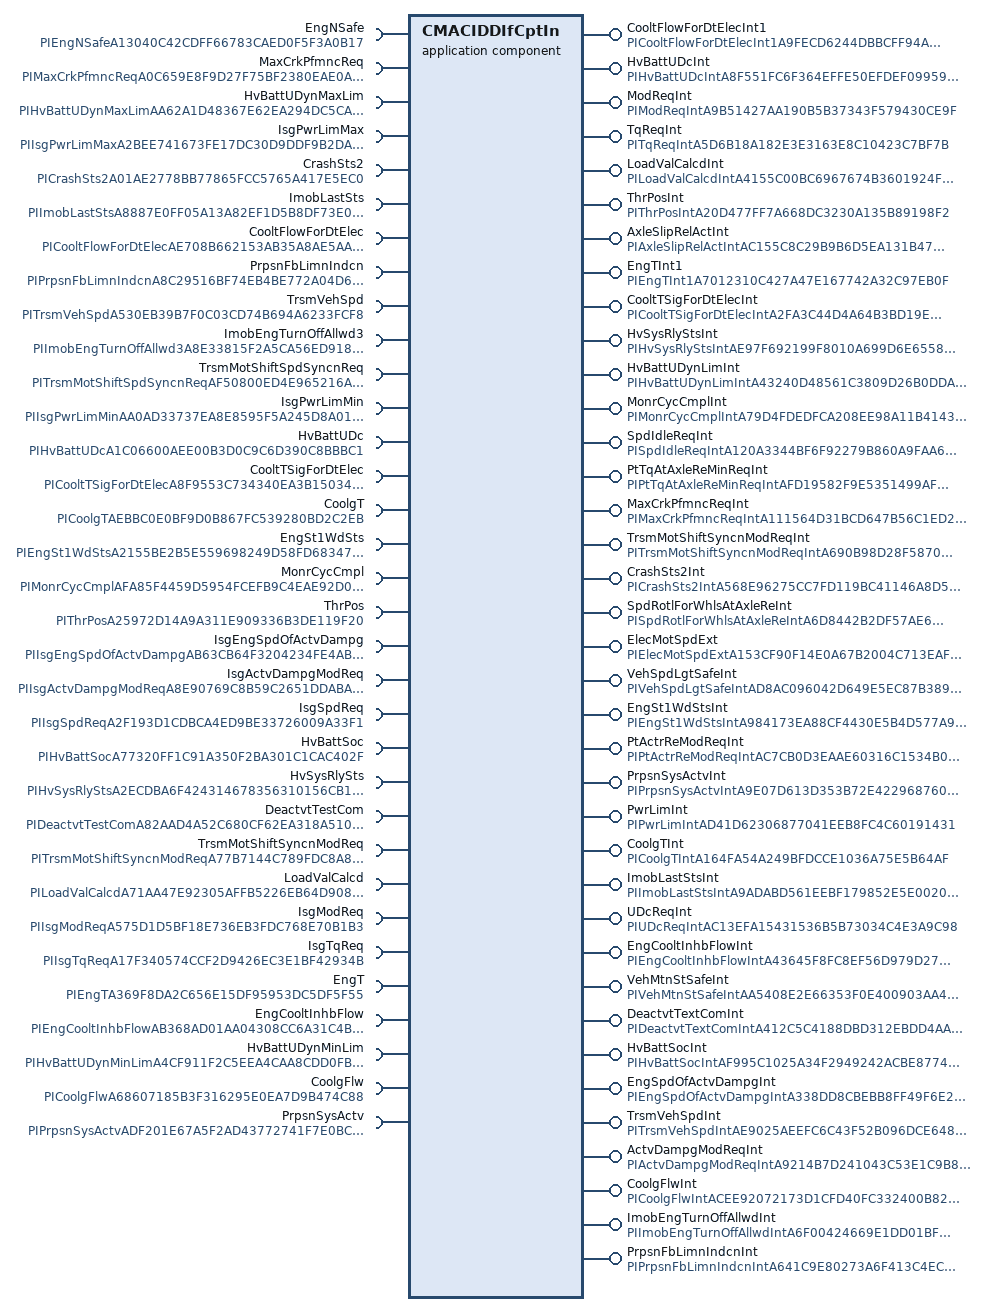
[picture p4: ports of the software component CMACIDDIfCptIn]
  application sw component type CMACIDDIfCptIn
    4 x require port:
      EngNSafe: nonqueued-receiver-com-spec{data-element=EngNSafe, init-value=constant-reference=A1AD216C2FE294940F0F0050DE621F46}, required-interface=PIEngNSafeA13040C42CDFF66783CAED0F5F3A0B17
      MaxCrkPfmncReq: nonqueued-receiver-com-spec{data-element=MaxCrkPfmncReq, init-value=constant-reference=A2AB2663EDCB674997EFCB4941EAE573}, required-interface=PIMaxCrkPfmncReqA0C659E8F9D27F75BF2380EAE0AA9F4B
      HvBattUDynMaxLim: nonqueued-receiver-com-spec{data-element=HvBattUDynMaxLim, init-value=constant-reference=A566A6590FA167C633F64C4171ADCCB7}, required-interface=PIHvBattUDynMaxLimAA62A1D48367E62EA294DC5CAB54933C
      IsgPwrLimMax: nonqueued-receiver-com-spec{data-element=IsgPwrLimMax, init-value=constant-reference=A566A6590FA167C633F64C4171ADCCB7}, required-interface=PIIsgPwrLimMaxA2BEE741673FE17DC30D9DDF9B2DA05E
    provide port CooltFlowForDtElecInt1: nonqueued-sender-com-spec{data-element=CooltFlowForDtElecInt1, init-value=constant-reference=A566A6590FA167C633F64C4171ADCCB7}, provided-interface=PICooltFlowForDtElecInt1A9FECD6244DBBCFF94A4D3481557ACF8
    require port CrashSts2: nonqueued-receiver-com-spec{data-element=CrashSts2, init-value=constant-reference=AD30053758475D867C29EE0F5723584A}, required-interface=PICrashSts2A01AE2778BB77865FCC5765A417E5EC0
    require port ImobLastSts: nonqueued-receiver-com-spec{data-element=ImobLastSts, init-value=constant-reference=A2AB2663EDCB674997EFCB4941EAE573}, required-interface=PIImobLastStsA8887E0FF05A13A82EF1D5B8DF73E036
    provide port HvBattUDcInt: nonqueued-sender-com-spec{data-element=HvBattUDcInt, init-value=constant-reference=A566A6590FA167C633F64C4171ADCCB7}, provided-interface=PIHvBattUDcIntA8F551FC6F364EFFE50EFDEF09959371
    provide port ModReqInt: nonqueued-sender-com-spec{data-element=ModReqInt, init-value=constant-reference=A5E6433C0EBBF7A278234C60E9932635}, provided-interface=PIModReqIntA9B51427AA190B5B37343F579430CE9F
    require port CooltFlowForDtElec: nonqueued-receiver-com-spec{data-element=CooltFlowForDtElec, init-value=constant-reference=A566A6590FA167C633F64C4171ADCCB7}, required-interface=PICooltFlowForDtElecAE708B662153AB35A8AE5AAB5AB27F45
    provide port TqReqInt: nonqueued-sender-com-spec{data-element=TqReqInt, init-value=constant-reference=A566A6590FA167C633F64C4171ADCCB7}, provided-interface=PITqReqIntA5D6B18A182E3E3163E8C10423C7BF7B
    require port PrpsnFbLimnIndcn: nonqueued-receiver-com-spec{data-element=PrpsnFbLimnIndcn, init-value=constant-reference=A2AB2663EDCB674997EFCB4941EAE573}, required-interface=PIPrpsnFbLimnIndcnA8C29516BF74EB4BE772A04D646D70E9
    provide port LoadValCalcdInt: nonqueued-sender-com-spec{data-element=LoadValCalcdInt, init-value=constant-reference=A566A6590FA167C633F64C4171ADCCB7}, provided-interface=PILoadValCalcdIntA4155C00BC6967674B3601924F63EF93
    provide port ThrPosInt: nonqueued-sender-com-spec{data-element=ThrPosInt, init-value=constant-reference=A566A6590FA167C633F64C4171ADCCB7}, provided-interface=PIThrPosIntA20D477FF7A668DC3230A135B89198F2
    provide port AxleSlipRelActInt: nonqueued-sender-com-spec{data-element=AxleSlipRelActInt, init-value=constant-reference=A566A6590FA167C633F64C4171ADCCB7}, provided-interface=PIAxleSlipRelActIntAC155C8C29B9B6D5EA131B477AEAA643
    require port TrsmVehSpd: nonqueued-receiver-com-spec{data-element=TrsmVehSpd, init-value=constant-reference=A566A6590FA167C633F64C4171ADCCB7}, required-interface=PITrsmVehSpdA530EB39B7F0C03CD74B694A6233FCF8
    require port ImobEngTurnOffAllwd3: nonqueued-receiver-com-spec{data-element=ImobEngTurnOffAllwd3, init-value=constant-reference=A2AB2663EDCB674997EFCB4941EAE573}, required-interface=PIImobEngTurnOffAllwd3A8E33815F2A5CA56ED918D0B41C26BA7
    provide port EngTInt1: nonqueued-sender-com-spec{data-element=EngTInt1, init-value=constant-reference=AD7F32376661EA365B8999AB28B9293D}, provided-interface=PIEngTInt1A7012310C427A47E167742A32C97EB0F
    require port TrsmMotShiftSpdSyncnReq: nonqueued-receiver-com-spec{data-element=TrsmMotShiftSpdSyncnReq, init-value=constant-reference=A566A6590FA167C633F64C4171ADCCB7}, required-interface=PITrsmMotShiftSpdSyncnReqAF50800ED4E965216A820B6F93CDEA6B
    provide port CooltTSigForDtElecInt: nonqueued-sender-com-spec{data-element=CooltTSigForDtElecInt, init-value=constant-reference=A566A6590FA167C633F64C4171ADCCB7}, provided-interface=PICooltTSigForDtElecIntA2FA3C44D4A64B3BD19E1FAA3F5036C0
    4 x require port:
      IsgPwrLimMin: nonqueued-receiver-com-spec{data-element=IsgPwrLimMin, init-value=constant-reference=A566A6590FA167C633F64C4171ADCCB7}, required-interface=PIIsgPwrLimMinAA0AD33737EA8E8595F5A245D8A01AAE
      HvBattUDc: nonqueued-receiver-com-spec{data-element=HvBattUDc, init-value=constant-reference=A566A6590FA167C633F64C4171ADCCB7}, required-interface=PIHvBattUDcA1C06600AEE00B3D0C9C6D390C8BBBC1
      CooltTSigForDtElec: nonqueued-receiver-com-spec{data-element=CooltTSigForDtElec, init-value=constant-reference=A566A6590FA167C633F64C4171ADCCB7}, required-interface=PICooltTSigForDtElecA8F9553C734340EA3B15034831232D8D
      CoolgT: nonqueued-receiver-com-spec{data-element=CoolgT, init-value=constant-reference=A2AB2663EDCB674997EFCB4941EAE573}, required-interface=PICoolgTAEBBC0E0BF9D0B867FC539280BD2C2EB
    provide port HvSysRlyStsInt: nonqueued-sender-com-spec{data-element=HvSysRlyStsInt, init-value=constant-reference=A2AB2663EDCB674997EFCB4941EAE573}, provided-interface=PIHvSysRlyStsIntAE97F692199F8010A699D6E6558D46BB
    provide port HvBattUDynLimInt: nonqueued-sender-com-spec{data-element=HvBattUDynLimInt, init-value=constant-reference=A6571BE8D08FA8624FE034351C65BBB8}, provided-interface=PIHvBattUDynLimIntA43240D48561C3809D26B0DDADA0994C
    require port EngSt1WdSts: nonqueued-receiver-com-spec{data-element=EngSt1WdSts, init-value=constant-reference=A636F88E591B4F4A2849AD5E95838F02}, required-interface=PIEngSt1WdStsA2155BE2B5E559698249D58FD6834766
    4 x provide port:
      MonrCycCmplInt: nonqueued-sender-com-spec{data-element=MonrCycCmplInt, init-value=constant-reference=AD30053758475D867C29EE0F5723584A}, provided-interface=PIMonrCycCmplIntA79D4FDEDFCA208EE98A11B4143D332E
      SpdIdleReqInt: nonqueued-sender-com-spec{data-element=SpdIdleReqInt, init-value=constant-reference=A566A6590FA167C633F64C4171ADCCB7}, provided-interface=PISpdIdleReqIntA120A3344BF6F92279B860A9FAA6ECAE
      PtTqAtAxleReMinReqInt: nonqueued-sender-com-spec{data-element=PtTqAtAxleReMinReqInt, init-value=constant-reference=AB2213CC11E3B1591DBD2F09CF632E62}, provided-interface=PIPtTqAtAxleReMinReqIntAFD19582F9E5351499AF05A089486D9F
      MaxCrkPfmncReqInt: nonqueued-sender-com-spec{data-element=MaxCrkPfmncReqInt, init-value=constant-reference=A2AB2663EDCB674997EFCB4941EAE573}, provided-interface=PIMaxCrkPfmncReqIntA111564D31BCD647B56C1ED2AC778042
    require port MonrCycCmpl: nonqueued-receiver-com-spec{data-element=MonrCycCmpl, init-value=constant-reference=AD30053758475D867C29EE0F5723584A}, required-interface=PIMonrCycCmplAFA85F4459D5954FCEFB9C4EAE92D0A0
    provide port TrsmMotShiftSyncnModReqInt: nonqueued-sender-com-spec{data-element=TrsmMotShiftSyncnModReqInt, init-value=constant-reference=A2AB2663EDCB674997EFCB4941EAE573}, provided-interface=PITrsmMotShiftSyncnModReqIntA690B98D28F58708C7741593A47EC6F4
    require port ThrPos: nonqueued-receiver-com-spec{data-element=ThrPos, init-value=constant-reference=A566A6590FA167C633F64C4171ADCCB7}, required-interface=PIThrPosA25972D14A9A311E909336B3DE119F20
    provide port CrashSts2Int: nonqueued-sender-com-spec{data-element=CrashSts2Int, init-value=constant-reference=AD30053758475D867C29EE0F5723584A}, provided-interface=PICrashSts2IntA568E96275CC7FD119BC41146A8D528D
    provide port SpdRotlForWhlsAtAxleReInt: nonqueued-sender-com-spec{data-element=SpdRotlForWhlsAtAxleReInt, init-value=constant-reference=A566A6590FA167C633F64C4171ADCCB7}, provided-interface=PISpdRotlForWhlsAtAxleReIntA6D8442B2DF57AE61F7FA90FE332F100
    require port IsgEngSpdOfActvDampg: nonqueued-receiver-com-spec{data-element=IsgEngSpdOfActvDampg, init-value=constant-reference=A566A6590FA167C633F64C4171ADCCB7}, required-interface=PIIsgEngSpdOfActvDampgAB63CB64F3204234FE4ABC77BFA3477D
    require port IsgActvDampgModReq: nonqueued-receiver-com-spec{data-element=IsgActvDampgModReq, init-value=constant-reference=A2AB2663EDCB674997EFCB4941EAE573}, required-interface=PIIsgActvDampgModReqA8E90769C8B59C2651DDABA1191E244E
    provide port ElecMotSpdExt: nonqueued-sender-com-spec{data-element=ElecMotSpdExt, init-value=constant-reference=A566A6590FA167C633F64C4171ADCCB7}, provided-interface=PIElecMotSpdExtA153CF90F14E0A67B2004C713EAF537C
    require port IsgSpdReq: nonqueued-receiver-com-spec{data-element=IsgSpdReq, init-value=constant-reference=A566A6590FA167C633F64C4171ADCCB7}, required-interface=PIIsgSpdReqA2F193D1CDBCA4ED9BE33726009A33F1
    require port HvBattSoc: nonqueued-receiver-com-spec{data-element=HvBattSoc, init-value=constant-reference=A566A6590FA167C633F64C4171ADCCB7}, required-interface=PIHvBattSocA77320FF1C91A350F2BA301C1CAC402F
    provide port VehSpdLgtSafeInt: nonqueued-sender-com-spec{data-element=VehSpdLgtSafeInt, init-value=constant-reference=A68FE985916865C70A611D0FFC6B9CF2}, provided-interface=PIVehSpdLgtSafeIntAD8AC096042D649E5EC87B3898F1B812
    require port HvSysRlySts: nonqueued-receiver-com-spec{data-element=HvSysRlySts, init-value=constant-reference=A2AB2663EDCB674997EFCB4941EAE573}, required-interface=PIHvSysRlyStsA2ECDBA6F424314678356310156CB116
    require port DeactvtTestCom: nonqueued-receiver-com-spec{data-element=DeactvtTestCom, init-value=constant-reference=AD30053758475D867C29EE0F5723584A}, required-interface=PIDeactvtTestComA82AAD4A52C680CF62EA318A5104AC68
    6 x provide port:
      EngSt1WdStsInt: nonqueued-sender-com-spec{data-element=EngSt1WdStsInt, init-value=constant-reference=A636F88E591B4F4A2849AD5E95838F02}, provided-interface=PIEngSt1WdStsIntA984173EA88CF4430E5B4D577A9BEE8A
      PtActrReModReqInt: nonqueued-sender-com-spec{data-element=PtActrReModReqInt, init-value=constant-reference=A2AB2663EDCB674997EFCB4941EAE573}, provided-interface=PIPtActrReModReqIntAC7CB0D3EAAE60316C1534B0170413A6
      PrpsnSysActvInt: nonqueued-sender-com-spec{data-element=PrpsnSysActvInt, init-value=constant-reference=AD30053758475D867C29EE0F5723584A}, provided-interface=PIPrpsnSysActvIntA9E07D613D353B72E4229687608CB35B
      PwrLimInt: nonqueued-sender-com-spec{data-element=PwrLimInt, init-value=constant-reference=A6571BE8D08FA8624FE034351C65BBB8}, provided-interface=PIPwrLimIntAD41D62306877041EEB8FC4C60191431
      CoolgTInt: nonqueued-sender-com-spec{data-element=CoolgTInt, init-value=constant-reference=A566A6590FA167C633F64C4171ADCCB7}, provided-interface=PICoolgTIntA164FA54A249BFDCCE1036A75E5B64AF
      ImobLastStsInt: nonqueued-sender-com-spec{data-element=ImobLastStsInt, init-value=constant-reference=A2AB2663EDCB674997EFCB4941EAE573}, provided-interface=PIImobLastStsIntA9ADABD561EEBF179852E5E0020F68FB
    require port TrsmMotShiftSyncnModReq: nonqueued-receiver-com-spec{data-element=TrsmMotShiftSyncnModReq, init-value=constant-reference=A2AB2663EDCB674997EFCB4941EAE573}, required-interface=PITrsmMotShiftSyncnModReqA77B7144C789FDC8A8DF5097F76BCE02
    require port LoadValCalcd: nonqueued-receiver-com-spec{data-element=LoadValCalcd, init-value=constant-reference=A566A6590FA167C633F64C4171ADCCB7}, required-interface=PILoadValCalcdA71AA47E92305AFFB5226EB64D908D0B
    require port IsgModReq: nonqueued-receiver-com-spec{data-element=IsgModReq, init-value=constant-reference=A2AB2663EDCB674997EFCB4941EAE573}, required-interface=PIIsgModReqA575D1D5BF18E736EB3FDC768E70B1B3
    provide port UDcReqInt: nonqueued-sender-com-spec{data-element=UDcReqInt, init-value=constant-reference=A566A6590FA167C633F64C4171ADCCB7}, provided-interface=PIUDcReqIntAC13EFA15431536B5B73034C4E3A9C98
    require port IsgTqReq: nonqueued-receiver-com-spec{data-element=IsgTqReq, init-value=constant-reference=A566A6590FA167C633F64C4171ADCCB7}, required-interface=PIIsgTqReqA17F340574CCF2D9426EC3E1BF42934B
    require port EngT: nonqueued-receiver-com-spec{data-element=EngT, init-value=constant-reference=AD7F32376661EA365B8999AB28B9293D}, required-interface=PIEngTA369F8DA2C656E15DF95953DC5DF5F55
    require port EngCooltInhbFlow: nonqueued-receiver-com-spec{data-element=EngCooltInhbFlow, init-value=constant-reference=A2AB2663EDCB674997EFCB4941EAE573}, required-interface=PIEngCooltInhbFlowAB368AD01AA04308CC6A31C4B6A4CDEC
    provide port EngCooltInhbFlowInt: nonqueued-sender-com-spec{data-element=EngCooltInhbFlowInt, init-value=constant-reference=A2AB2663EDCB674997EFCB4941EAE573}, provided-interface=PIEngCooltInhbFlowIntA43645F8FC8EF56D979D27462C05E480
    provide port VehMtnStSafeInt: nonqueued-sender-com-spec{data-element=VehMtnStSafeInt, init-value=constant-reference=AFC8E6EC384951247C75A8CAF348B75E}, provided-interface=PIVehMtnStSafeIntAA5408E2E66353F0E400903AA4B73408
    provide port DeactvtTextComInt: nonqueued-sender-com-spec{data-element=DeactvtTextComInt, init-value=constant-reference=A2AB2663EDCB674997EFCB4941EAE573}, provided-interface=PIDeactvtTextComIntA412C5C4188DBD312EBDD4AACDF5606F
    require port HvBattUDynMinLim: nonqueued-receiver-com-spec{data-element=HvBattUDynMinLim, init-value=constant-reference=A566A6590FA167C633F64C4171ADCCB7}, required-interface=PIHvBattUDynMinLimA4CF911F2C5EEA4CAA8CDD0FB3E6AE92
    provide port HvBattSocInt: nonqueued-sender-com-spec{data-element=HvBattSocInt, init-value=constant-reference=A566A6590FA167C633F64C4171ADCCB7}, provided-interface=PIHvBattSocIntAF995C1025A34F2949242ACBE8774947
    require port CoolgFlw: nonqueued-receiver-com-spec{data-element=CoolgFlw, init-value=constant-reference=A566A6590FA167C633F64C4171ADCCB7}, required-interface=PICoolgFlwA68607185B3F316295E0EA7D9B474C88
    require port PrpsnSysActv: nonqueued-receiver-com-spec{data-element=PrpsnSysActv, init-value=constant-reference=A2AB2663EDCB674997EFCB4941EAE573}, required-interface=PIPrpsnSysActvADF201E67A5F2AD43772741F7E0BC64C
    6 x provide port:
      EngSpdOfActvDampgInt: nonqueued-sender-com-spec{data-element=EngSpdOfActvDampgInt, init-value=constant-reference=A566A6590FA167C633F64C4171ADCCB7}, provided-interface=PIEngSpdOfActvDampgIntA338DD8CBEBB8FF49F6E29D8BC113090
      TrsmVehSpdInt: nonqueued-sender-com-spec{data-element=TrsmVehSpdInt, init-value=constant-reference=A566A6590FA167C633F64C4171ADCCB7}, provided-interface=PITrsmVehSpdIntAE9025AEEFC6C43F52B096DCE648E8B2
      ActvDampgModReqInt: nonqueued-sender-com-spec{data-element=ActvDampgModReqInt, init-value=constant-reference=A2AB2663EDCB674997EFCB4941EAE573}, provided-interface=PIActvDampgModReqIntA9214B7D241043C53E1C9B8E4812B73E
      CoolgFlwInt: nonqueued-sender-com-spec{data-element=CoolgFlwInt, init-value=constant-reference=A566A6590FA167C633F64C4171ADCCB7}, provided-interface=PICoolgFlwIntACEE92072173D1CFD40FC332400B8271
      ImobEngTurnOffAllwdInt: nonqueued-sender-com-spec{data-element=ImobEngTurnOffAllwdInt, init-value=constant-reference=A2AB2663EDCB674997EFCB4941EAE573}, provided-interface=PIImobEngTurnOffAllwdIntA6F00424669E1DD01BF13F084E9A5B01
      PrpsnFbLimnIndcnInt: nonqueued-sender-com-spec{data-element=PrpsnFbLimnIndcnInt, init-value=constant-reference=A2AB2663EDCB674997EFCB4941EAE573}, provided-interface=PIPrpsnFbLimnIndcnIntA641C9E80273A6F413C4ECAECEAF8225
    behavior BE7a16c38fa845c98468f74eb3c94195: handle-termination-and-restart=NO-SUPPORT
      port-api-options:
        enable-take-address=false, indirect-api=false, port=CMACIDDIfCptIn/EngNSafe
        enable-take-address=false, indirect-api=false, port=CMACIDDIfCptIn/MaxCrkPfmncReq
        enable-take-address=false, indirect-api=false, port=CMACIDDIfCptIn/HvBattUDynMaxLim
        enable-take-address=false, indirect-api=false, port=CMACIDDIfCptIn/IsgPwrLimMax
        enable-take-address=false, indirect-api=false, port=CMACIDDIfCptIn/CooltFlowForDtElecInt1
        enable-take-address=false, indirect-api=false, port=CMACIDDIfCptIn/CrashSts2
        enable-take-address=false, indirect-api=false, port=CMACIDDIfCptIn/ImobLastSts
        enable-take-address=false, indirect-api=false, port=CMACIDDIfCptIn/HvBattUDcInt
        enable-take-address=false, indirect-api=false, port=ModReqInt
        enable-take-address=false, indirect-api=false, port=CMACIDDIfCptIn/CooltFlowForDtElec
        enable-take-address=false, indirect-api=false, port=TqReqInt
        enable-take-address=false, indirect-api=false, port=CMACIDDIfCptIn/PrpsnFbLimnIndcn
        enable-take-address=false, indirect-api=false, port=CMACIDDIfCptIn/LoadValCalcdInt
        enable-take-address=false, indirect-api=false, port=CMACIDDIfCptIn/ThrPosInt
        enable-take-address=false, indirect-api=false, port=AxleSlipRelActInt
        enable-take-address=false, indirect-api=false, port=CMACIDDIfCptIn/TrsmVehSpd
        enable-take-address=false, indirect-api=false, port=CMACIDDIfCptIn/ImobEngTurnOffAllwd3
        enable-take-address=false, indirect-api=false, port=CMACIDDIfCptIn/EngTInt1
        enable-take-address=false, indirect-api=false, port=CMACIDDIfCptIn/TrsmMotShiftSpdSyncnReq
        enable-take-address=false, indirect-api=false, port=CMACIDDIfCptIn/CooltTSigForDtElecInt
        enable-take-address=false, indirect-api=false, port=CMACIDDIfCptIn/IsgPwrLimMin
        enable-take-address=false, indirect-api=false, port=CMACIDDIfCptIn/HvBattUDc
        enable-take-address=false, indirect-api=false, port=CMACIDDIfCptIn/CooltTSigForDtElec
        enable-take-address=false, indirect-api=false, port=CMACIDDIfCptIn/CoolgT
        enable-take-address=false, indirect-api=false, port=CMACIDDIfCptIn/HvSysRlyStsInt
        enable-take-address=false, indirect-api=false, port=HvBattUDynLimInt
        enable-take-address=false, indirect-api=false, port=CMACIDDIfCptIn/EngSt1WdSts
        enable-take-address=false, indirect-api=false, port=CMACIDDIfCptIn/MonrCycCmplInt
        enable-take-address=false, indirect-api=false, port=SpdIdleReqInt
        enable-take-address=false, indirect-api=false, port=PtTqAtAxleReMinReqInt
        enable-take-address=false, indirect-api=false, port=MaxCrkPfmncReqInt
        enable-take-address=false, indirect-api=false, port=CMACIDDIfCptIn/MonrCycCmpl
        enable-take-address=false, indirect-api=false, port=TrsmMotShiftSyncnModReqInt
        enable-take-address=false, indirect-api=false, port=CMACIDDIfCptIn/ThrPos
        enable-take-address=false, indirect-api=false, port=CrashSts2Int
        enable-take-address=false, indirect-api=false, port=SpdRotlForWhlsAtAxleReInt
        enable-take-address=false, indirect-api=false, port=CMACIDDIfCptIn/IsgEngSpdOfActvDampg
        enable-take-address=false, indirect-api=false, port=CMACIDDIfCptIn/IsgActvDampgModReq
        enable-take-address=false, indirect-api=false, port=CMACIDDIfCptIn/ElecMotSpdExt
        enable-take-address=false, indirect-api=false, port=CMACIDDIfCptIn/IsgSpdReq
        enable-take-address=false, indirect-api=false, port=CMACIDDIfCptIn/HvBattSoc
        enable-take-address=false, indirect-api=false, port=VehSpdLgtSafeInt
        enable-take-address=false, indirect-api=false, port=CMACIDDIfCptIn/HvSysRlySts
        enable-take-address=false, indirect-api=false, port=CMACIDDIfCptIn/DeactvtTestCom
        enable-take-address=false, indirect-api=false, port=CMACIDDIfCptIn/EngSt1WdStsInt
        enable-take-address=false, indirect-api=false, port=PtActrReModReqInt
        enable-take-address=false, indirect-api=false, port=CMACIDDIfCptIn/PrpsnSysActvInt
        enable-take-address=false, indirect-api=false, port=PwrLimInt
        enable-take-address=false, indirect-api=false, port=CoolgTInt
        enable-take-address=false, indirect-api=false, port=ImobLastStsInt
        enable-take-address=false, indirect-api=false, port=CMACIDDIfCptIn/TrsmMotShiftSyncnModReq
        enable-take-address=false, indirect-api=false, port=CMACIDDIfCptIn/LoadValCalcd
        enable-take-address=false, indirect-api=false, port=CMACIDDIfCptIn/IsgModReq
        enable-take-address=false, indirect-api=false, port=UDcReqInt
        enable-take-address=false, indirect-api=false, port=CMACIDDIfCptIn/IsgTqReq
        enable-take-address=false, indirect-api=false, port=CMACIDDIfCptIn/EngT
        enable-take-address=false, indirect-api=false, port=CMACIDDIfCptIn/EngCooltInhbFlow
        enable-take-address=false, indirect-api=false, port=EngCooltInhbFlowInt
        enable-take-address=false, indirect-api=false, port=VehMtnStSafeInt
        enable-take-address=false, indirect-api=false, port=DeactvtTextComInt
        enable-take-address=false, indirect-api=false, port=CMACIDDIfCptIn/HvBattUDynMinLim
        enable-take-address=false, indirect-api=false, port=CMACIDDIfCptIn/HvBattSocInt
        enable-take-address=false, indirect-api=false, port=CMACIDDIfCptIn/CoolgFlw
        enable-take-address=false, indirect-api=false, port=CMACIDDIfCptIn/PrpsnSysActv
        enable-take-address=false, indirect-api=false, port=EngSpdOfActvDampgInt
        enable-take-address=false, indirect-api=false, port=CMACIDDIfCptIn/TrsmVehSpdInt
        enable-take-address=false, indirect-api=false, port=ActvDampgModReqInt
        enable-take-address=false, indirect-api=false, port=CoolgFlwInt
        enable-take-address=false, indirect-api=false, port=ImobEngTurnOffAllwdInt
        enable-take-address=false, indirect-api=false, port=PrpsnFbLimnIndcnInt
package /ComponentType/IvtrPwrLimn/IvtrPwrLimnMAIN
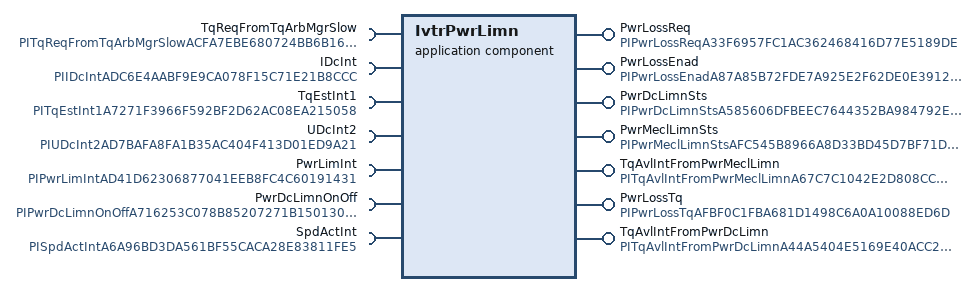
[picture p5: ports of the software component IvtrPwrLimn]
  application sw component type IvtrPwrLimn
    provide port PwrLossReq: nonqueued-sender-com-spec{data-element=PwrLossReq, init-value=constant-reference=A566A6590FA167C633F64C4171ADCCB7}, provided-interface=PIPwrLossReqA33F6957FC1AC362468416D77E5189DE
    require port TqReqFromTqArbMgrSlow: nonqueued-receiver-com-spec{data-element=TqReqFromTqArbMgrSlow, init-value=constant-reference=A566A6590FA167C633F64C4171ADCCB7}, required-interface=PITqReqFromTqArbMgrSlowACFA7EBE680724BB6B16A7641540B266
    require port IDcInt: nonqueued-receiver-com-spec{data-element=IDcInt, init-value=constant-reference=A566A6590FA167C633F64C4171ADCCB7}, required-interface=PIIDcIntADC6E4AABF9E9CA078F15C71E21B8CCC
    provide port PwrLossEnad: nonqueued-sender-com-spec{data-element=PwrLossEnad, init-value=constant-reference=A2AB2663EDCB674997EFCB4941EAE573}, provided-interface=PIPwrLossEnadA87A85B72FDE7A925E2F62DE0E3912FE
    provide port PwrDcLimnSts: nonqueued-sender-com-spec{data-element=PwrDcLimnSts, init-value=constant-reference=A2AB2663EDCB674997EFCB4941EAE573}, provided-interface=PIPwrDcLimnStsA585606DFBEEC7644352BA984792E3DF
    require port TqEstInt1: nonqueued-receiver-com-spec{data-element=TqEstInt1, init-value=constant-reference=A566A6590FA167C633F64C4171ADCCB7}, required-interface=PITqEstInt1A7271F3966F592BF2D62AC08EA215058
    require port UDcInt2: nonqueued-receiver-com-spec{data-element=UDcInt2, init-value=constant-reference=A566A6590FA167C633F64C4171ADCCB7}, required-interface=PIUDcInt2AD7BAFA8FA1B35AC404F413D01ED9A21
    require port PwrLimInt: nonqueued-receiver-com-spec{data-element=PwrLimInt, init-value=constant-reference=A6571BE8D08FA8624FE034351C65BBB8}, required-interface=PIPwrLimIntAD41D62306877041EEB8FC4C60191431
    provide port PwrMeclLimnSts: nonqueued-sender-com-spec{data-element=PwrMeclLimnSts, init-value=constant-reference=A2AB2663EDCB674997EFCB4941EAE573}, provided-interface=PIPwrMeclLimnStsAFC545B8966A8D33BD45D7BF71D6D720
    provide port TqAvlIntFromPwrMeclLimn: nonqueued-sender-com-spec{data-element=TqAvlIntFromPwrMeclLimn, init-value=constant-reference=A8CFFE3621C1DA13E6FF691AE3A9D3C1}, provided-interface=PITqAvlIntFromPwrMeclLimnA67C7C1042E2D808CCF62C1CA5324947
    provide port PwrLossTq: nonqueued-sender-com-spec{data-element=PwrLossTq, init-value=constant-reference=A566A6590FA167C633F64C4171ADCCB7}, provided-interface=PIPwrLossTqAFBF0C1FBA681D1498C6A0A10088ED6D
    require port PwrDcLimnOnOff: nonqueued-receiver-com-spec{data-element=PwrDcLimnOnOff, init-value=constant-reference=A2AB2663EDCB674997EFCB4941EAE573}, required-interface=PIPwrDcLimnOnOffA716253C078B85207271B150130ACE4C
    require port SpdActInt: nonqueued-receiver-com-spec{data-element=SpdActInt, init-value=constant-reference=A566A6590FA167C633F64C4171ADCCB7}, required-interface=PISpdActIntA6A96BD3DA561BF55CACA28E83811FE5
    provide port TqAvlIntFromPwrDcLimn: nonqueued-sender-com-spec{data-element=TqAvlIntFromPwrDcLimn, init-value=constant-reference=A6571BE8D08FA8624FE034351C65BBB8}, provided-interface=PITqAvlIntFromPwrDcLimnA44A5404E5169E40ACC2FA97F3F218EE
    behavior BE077267a01048b0943664ac9ace45e3: handle-termination-and-restart=NO-SUPPORT
      port-api-options:
        enable-take-address=false, indirect-api=false, port=IvtrPwrLimn/PwrLossReq
        enable-take-address=false, indirect-api=false, port=IvtrPwrLimn/TqReqFromTqArbMgrSlow
        enable-take-address=false, indirect-api=false, port=IvtrPwrLimn/IDcInt
        enable-take-address=false, indirect-api=false, port=PwrLossEnad
        enable-take-address=false, indirect-api=false, port=PwrDcLimnSts
        enable-take-address=false, indirect-api=false, port=IvtrPwrLimn/TqEstInt1
        enable-take-address=false, indirect-api=false, port=IvtrPwrLimn/UDcInt2
        enable-take-address=false, indirect-api=false, port=PwrLimInt
        enable-take-address=false, indirect-api=false, port=PwrMeclLimnSts
        enable-take-address=false, indirect-api=false, port=TqAvlIntFromPwrMeclLimn
        enable-take-address=false, indirect-api=false, port=PwrLossTq
        enable-take-address=false, indirect-api=false, port=PwrDcLimnOnOff
        enable-take-address=false, indirect-api=false, port=IvtrPwrLimn/SpdActInt
        enable-take-address=false, indirect-api=false, port=TqAvlIntFromPwrDcLimn
package /ComponentType/IvtrLimnIndcn/IvtrLimnIndcnMAIN
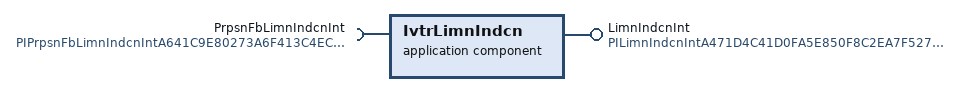
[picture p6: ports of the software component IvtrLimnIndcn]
  application sw component type IvtrLimnIndcn
    provide port LimnIndcnInt: nonqueued-sender-com-spec{data-element=LimnIndcnInt, init-value=constant-reference=A2AB2663EDCB674997EFCB4941EAE573}, provided-interface=PILimnIndcnIntA471D4C41D0FA5E850F8C2EA7F52740F
    require port PrpsnFbLimnIndcnInt: nonqueued-receiver-com-spec{data-element=PrpsnFbLimnIndcnInt, init-value=constant-reference=A2AB2663EDCB674997EFCB4941EAE573}, required-interface=PIPrpsnFbLimnIndcnIntA641C9E80273A6F413C4ECAECEAF8225
    behavior BE34b30cf0544e9e9cbcd214d0cda1fa: handle-termination-and-restart=NO-SUPPORT
      port-api-options:
        enable-take-address=false, indirect-api=false, port=LimnIndcnInt
        enable-take-address=false, indirect-api=false, port=PrpsnFbLimnIndcnInt
package /ComponentType/IvtrAntiShuffleCtrl/IvtrAntiShuffleCtrlMAIN
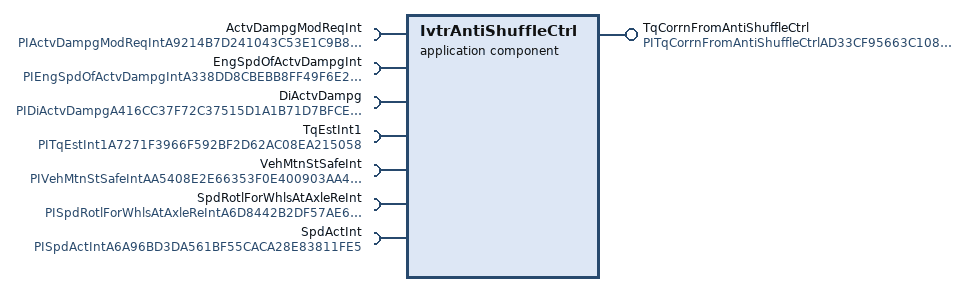
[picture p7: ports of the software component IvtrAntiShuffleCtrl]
  application sw component type IvtrAntiShuffleCtrl
    require port ActvDampgModReqInt: nonqueued-receiver-com-spec{data-element=ActvDampgModReqInt, init-value=constant-reference=A2AB2663EDCB674997EFCB4941EAE573}, required-interface=PIActvDampgModReqIntA9214B7D241043C53E1C9B8E4812B73E
    require port EngSpdOfActvDampgInt: nonqueued-receiver-com-spec{data-element=EngSpdOfActvDampgInt, init-value=constant-reference=A566A6590FA167C633F64C4171ADCCB7}, required-interface=PIEngSpdOfActvDampgIntA338DD8CBEBB8FF49F6E29D8BC113090
    provide port TqCorrnFromAntiShuffleCtrl: nonqueued-sender-com-spec{data-element=TqCorrnFromAntiShuffleCtrl, init-value=constant-reference=A566A6590FA167C633F64C4171ADCCB7}, provided-interface=PITqCorrnFromAntiShuffleCtrlAD33CF95663C108692593B0CC185952D
    5 x require port:
      DiActvDampg: nonqueued-receiver-com-spec{data-element=DiActvDampg, init-value=constant-reference=AD30053758475D867C29EE0F5723584A}, required-interface=PIDiActvDampgA416CC37F72C37515D1A1B71D7BFCE6B
      TqEstInt1: nonqueued-receiver-com-spec{data-element=TqEstInt1, init-value=constant-reference=A566A6590FA167C633F64C4171ADCCB7}, required-interface=PITqEstInt1A7271F3966F592BF2D62AC08EA215058
      VehMtnStSafeInt: nonqueued-receiver-com-spec{data-element=VehMtnStSafeInt, init-value=constant-reference=AFC8E6EC384951247C75A8CAF348B75E}, required-interface=PIVehMtnStSafeIntAA5408E2E66353F0E400903AA4B73408
      SpdRotlForWhlsAtAxleReInt: nonqueued-receiver-com-spec{data-element=SpdRotlForWhlsAtAxleReInt, init-value=constant-reference=A566A6590FA167C633F64C4171ADCCB7}, required-interface=PISpdRotlForWhlsAtAxleReIntA6D8442B2DF57AE61F7FA90FE332F100
      SpdActInt: nonqueued-receiver-com-spec{data-element=SpdActInt, init-value=constant-reference=A566A6590FA167C633F64C4171ADCCB7}, required-interface=PISpdActIntA6A96BD3DA561BF55CACA28E83811FE5
    behavior BE284302c43440008a5845cf791ba694: handle-termination-and-restart=NO-SUPPORT
      port-api-options:
        enable-take-address=false, indirect-api=false, port=ActvDampgModReqInt
        enable-take-address=false, indirect-api=false, port=EngSpdOfActvDampgInt
        enable-take-address=false, indirect-api=false, port=TqCorrnFromAntiShuffleCtrl
        enable-take-address=false, indirect-api=false, port=DiActvDampg
        enable-take-address=false, indirect-api=false, port=IvtrAntiShuffleCtrl/TqEstInt1
        enable-take-address=false, indirect-api=false, port=VehMtnStSafeInt
        enable-take-address=false, indirect-api=false, port=IvtrAntiShuffleCtrl/SpdRotlForWhlsAtAxleReInt
        enable-take-address=false, indirect-api=false, port=IvtrAntiShuffleCtrl/SpdActInt
package /ComponentType/IvtrSpdLimn/IvtrSpdLimnMAIN
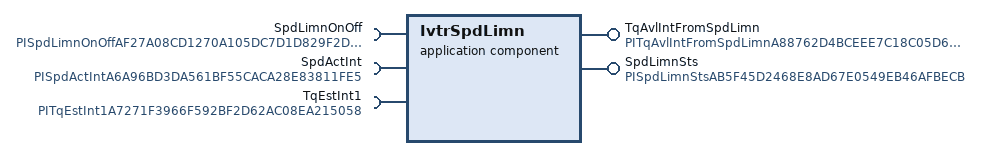
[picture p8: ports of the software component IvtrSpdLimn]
  application sw component type IvtrSpdLimn  # QM function to give a smooth speed limitation, something the ASIL-C rated function "Over-speed protection" might not be able to do.
    require port SpdLimnOnOff: nonqueued-receiver-com-spec{data-element=SpdLimnOnOff, init-value=constant-reference=A2AB2663EDCB674997EFCB4941EAE573}, required-interface=PISpdLimnOnOffAF27A08CD1270A105DC7D1D829F2DFFC
    provide port TqAvlIntFromSpdLimn: nonqueued-sender-com-spec{data-element=TqAvlIntFromSpdLimn, init-value=constant-reference=A8CFFE3621C1DA13E6FF691AE3A9D3C1}, provided-interface=PITqAvlIntFromSpdLimnA88762D4BCEEE7C18C05D620D2A53FB7
    provide port SpdLimnSts: nonqueued-sender-com-spec{data-element=SpdLimnSts, init-value=constant-reference=A2AB2663EDCB674997EFCB4941EAE573}, provided-interface=PISpdLimnStsAB5F45D2468E8AD67E0549EB46AFBECB
    require port SpdActInt: nonqueued-receiver-com-spec{data-element=SpdActInt, init-value=constant-reference=A566A6590FA167C633F64C4171ADCCB7}, required-interface=PISpdActIntA6A96BD3DA561BF55CACA28E83811FE5
    require port TqEstInt1: nonqueued-receiver-com-spec{data-element=TqEstInt1, init-value=constant-reference=A566A6590FA167C633F64C4171ADCCB7}, required-interface=PITqEstInt1A7271F3966F592BF2D62AC08EA215058
    behavior BE42cee44d2d46a389978c68bd4de2f0: handle-termination-and-restart=NO-SUPPORT
      port-api-options:
        enable-take-address=false, indirect-api=false, port=SpdLimnOnOff
        enable-take-address=false, indirect-api=false, port=TqAvlIntFromSpdLimn
        enable-take-address=false, indirect-api=false, port=SpdLimnSts
        enable-take-address=false, indirect-api=false, port=IvtrSpdLimn/SpdActInt
        enable-take-address=false, indirect-api=false, port=IvtrSpdLimn/TqEstInt1
package /ComponentType/IvtrStabyCtrl/IvtrStabyCtrlMAIN
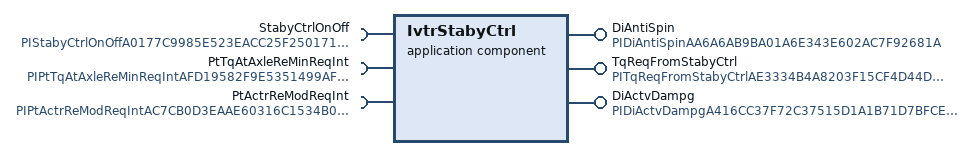
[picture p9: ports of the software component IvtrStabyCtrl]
  application sw component type IvtrStabyCtrl
    require port StabyCtrlOnOff: nonqueued-receiver-com-spec{data-element=StabyCtrlOnOff, init-value=constant-reference=A2AB2663EDCB674997EFCB4941EAE573}, required-interface=PIStabyCtrlOnOffA0177C9985E523EACC25F2501718EFA6
    provide port DiAntiSpin: nonqueued-sender-com-spec{data-element=DiAntiSpin, init-value=constant-reference=AD30053758475D867C29EE0F5723584A}, provided-interface=PIDiAntiSpinAA6A6AB9BA01A6E343E602AC7F92681A
    provide port TqReqFromStabyCtrl: nonqueued-sender-com-spec{data-element=TqReqFromStabyCtrl, init-value=constant-reference=A566A6590FA167C633F64C4171ADCCB7}, provided-interface=PITqReqFromStabyCtrlAE3334B4A8203F15CF4D44D6347AB2D9
    provide port DiActvDampg: nonqueued-sender-com-spec{data-element=DiActvDampg, init-value=constant-reference=A2AB2663EDCB674997EFCB4941EAE573}, provided-interface=PIDiActvDampgA416CC37F72C37515D1A1B71D7BFCE6B
    require port PtTqAtAxleReMinReqInt: nonqueued-receiver-com-spec{data-element=PtTqAtAxleReMinReqInt, init-value=constant-reference=AB2213CC11E3B1591DBD2F09CF632E62}, required-interface=PIPtTqAtAxleReMinReqIntAFD19582F9E5351499AF05A089486D9F
    require port PtActrReModReqInt: nonqueued-receiver-com-spec{data-element=PtActrReModReqInt, init-value=constant-reference=A2AB2663EDCB674997EFCB4941EAE573}, required-interface=PIPtActrReModReqIntAC7CB0D3EAAE60316C1534B0170413A6
    behavior BEfd3cb702884a41bf2d5bb4a7a36a02: handle-termination-and-restart=NO-SUPPORT
      port-api-options:
        enable-take-address=false, indirect-api=false, port=StabyCtrlOnOff
        enable-take-address=false, indirect-api=false, port=DiAntiSpin
        enable-take-address=false, indirect-api=false, port=TqReqFromStabyCtrl
        enable-take-address=false, indirect-api=false, port=DiActvDampg
        enable-take-address=false, indirect-api=false, port=PtTqAtAxleReMinReqInt
        enable-take-address=false, indirect-api=false, port=PtActrReModReqInt
package /ComponentType/IvtrActvDchaMgr/IvtrActvDchaMgrMAIN
  application sw component type IvtrActvDchaMgr
    require port HvSysRlyStsTiOut: nonqueued-receiver-com-spec{data-element=HvSysRlyStsTiOut, init-value=constant-reference=A2AB2663EDCB674997EFCB4941EAE573}, required-interface=PIHvSysRlyStsTiOutA38DC641039478964364ABA0D9653B7F
    require port CrashSts2Int: nonqueued-receiver-com-spec{data-element=CrashSts2Int, init-value=constant-reference=AD30053758475D867C29EE0F5723584A}, required-interface=PICrashSts2IntA568E96275CC7FD119BC41146A8D528D
    require port HvSysRlyStsInt: nonqueued-receiver-com-spec{data-element=HvSysRlyStsInt, init-value=constant-reference=AE6F9FB492BDC7FCA4CAB2BF64648C6A}, required-interface=PIHvSysRlyStsIntAE97F692199F8010A699D6E6558D46BB
    provide port ActvDchaReq: nonqueued-sender-com-spec{data-element=ActvDchaReq, init-value=constant-reference=A2AB2663EDCB674997EFCB4941EAE573}, provided-interface=PIActvDchaReqABDBFDA592F4FD97AEC36B8942FC52D1
    require port ActvDchaAvl: nonqueued-receiver-com-spec{data-element=ActvDchaAvl, init-value=constant-reference=A2AB2663EDCB674997EFCB4941EAE573}, required-interface=PIActvDchaAvlAF45BC8BAD28EC2A3C8040AFDD55349F
    require port UDcInt2: nonqueued-receiver-com-spec{data-element=UDcInt2, init-value=constant-reference=A566A6590FA167C633F64C4171ADCCB7}, required-interface=PIUDcInt2AD7BAFA8FA1B35AC404F413D01ED9A21
    behavior BE42e3e3e2f746daac601a8a05766b58: handle-termination-and-restart=NO-SUPPORT
      port-api-options:
        enable-take-address=false, indirect-api=false, port=IvtrActvDchaMgr/HvSysRlyStsTiOut
        enable-take-address=false, indirect-api=false, port=CrashSts2Int
        enable-take-address=false, indirect-api=false, port=IvtrActvDchaMgr/HvSysRlyStsInt
        enable-take-address=false, indirect-api=false, port=ActvDchaReq
        enable-take-address=false, indirect-api=false, port=IvtrActvDchaMgr/ActvDchaAvl
        enable-take-address=false, indirect-api=false, port=IvtrActvDchaMgr/UDcInt2
package /ComponentType/IvtrUSetCtrl/IvtrUSetCtrlMAIN
  application sw component type IvtrUSetCtrl
    require port TqReqMot: nonqueued-receiver-com-spec{data-element=TqReqMot, init-value=constant-reference=A566A6590FA167C633F64C4171ADCCB7}, required-interface=PITqReqMotAA0613566B952B165886BB90ACC9A333
    require port UDcReqInt: nonqueued-receiver-com-spec{data-element=UDcReqInt, init-value=constant-reference=A566A6590FA167C633F64C4171ADCCB7}, required-interface=PIUDcReqIntAC13EFA15431536B5B73034C4E3A9C98
    provide port TqReqFromUSetCtrl: nonqueued-sender-com-spec{data-element=TqReqFromUSetCtrl, init-value=constant-reference=A566A6590FA167C633F64C4171ADCCB7}, provided-interface=PITqReqFromUSetCtrlA1DCACFFC54FBD504C97AB823DEC438C
    require port USetCtrlMod: nonqueued-receiver-com-spec{data-element=USetCtrlMod, init-value=constant-reference=A2AB2663EDCB674997EFCB4941EAE573}, required-interface=PIUSetCtrlModA5DAD94277F1523660C82246E9CA1AEB
    require port HvSysRlyStsInt: nonqueued-receiver-com-spec{data-element=HvSysRlyStsInt, init-value=constant-reference=A2AB2663EDCB674997EFCB4941EAE573}, required-interface=PIHvSysRlyStsIntAE97F692199F8010A699D6E6558D46BB
    require port UDcInt2: nonqueued-receiver-com-spec{data-element=UDcInt2, init-value=constant-reference=A566A6590FA167C633F64C4171ADCCB7}, required-interface=PIUDcInt2AD7BAFA8FA1B35AC404F413D01ED9A21
    behavior BE4e31822df343d6834b014986a9fafe: handle-termination-and-restart=NO-SUPPORT
      port-api-options:
        enable-take-address=false, indirect-api=false, port=IvtrUSetCtrl/TqReqMot
        enable-take-address=false, indirect-api=false, port=UDcReqInt
        enable-take-address=false, indirect-api=false, port=TqReqFromUSetCtrl
        enable-take-address=false, indirect-api=false, port=USetCtrlMod
        enable-take-address=false, indirect-api=false, port=IvtrUSetCtrl/HvSysRlyStsInt
        enable-take-address=false, indirect-api=false, port=IvtrUSetCtrl/UDcInt2
